VERSION ""

NS_ :

BS_:

BU_: HU ICM BSDR TCO BCM TBOX LDWS BSDL

BO_ 683 BCM_2AB: 8 BCM
 SG_ SecurityStatus : 0|1@0+ (1,0) [0|1] ""  BSDL,BSDR
 SG_ SecurityAlarm : 1|1@0+ (1,0) [0|1] "" Vector__XXX
 SG_ DrvLockCommand : 5|4@0+ (1,0) [0|15] "" Vector__XXX
 SG_ KSEnable : 7|1@0+ (1,0) [0|1] "" Vector__XXX
 SG_ DRLLamp : 9|1@0+ (1,0) [0|1] ""  ICM
 SG_ DayNightStatus : 10|1@0+ (1,0) [0|1] "" Vector__XXX
 SG_ BCM_RemoteKeyID : 13|3@0+ (1,0) [0|7] "" Vector__XXX
 SG_ BackLightControl : 15|2@0+ (1,0) [0|3] "" Vector__XXX
 SG_ LockCtrl : 23|8@0+ (1,0) [0|255] "" Vector__XXX
 SG_ BCM_BackLightLvl : 31|8@0+ (0.4,0) [14.4|86.4] "%"  ICM
 SG_ DirIndicationLeft : 32|1@0+ (1,0) [0|1] ""  ICM,BSDL,BSDR
 SG_ DirIndicationRight : 33|1@0+ (1,0) [0|1] ""  ICM,BSDL,BSDR
 SG_ TurnSwitch : 35|2@0+ (1,0) [0|3] ""  BSDL,BSDR
 SG_ HandBrakingStatus : 36|1@0+ (1,0) [0|1] ""  ICM
 SG_ KeyState : 42|3@0+ (1,0) [0|7] ""  ICM,HU,BSDL,BSDR
 SG_ BCM_KeyState_VD : 44|2@0+ (1,0) [0|3] ""  ICM
 SG_ TurnSwitchVd : 45|1@0+ (1,0) [0|1] "" Vector__XXX
 SG_ WiperStatus : 47|2@0+ (1,0) [0|3] "" Vector__XXX
 SG_ KeyOnCounter : 55|16@0+ (1,0) [0|65534] "" Vector__XXX

BO_ 717 BCM_2CD: 8 BCM
 SG_ HazardWarningLightStatus : 0|1@0+ (1,0) [0|1] "" Vector__XXX
 SG_ RearWiperCtrl : 2|2@0+ (1,0) [0|3] "" Vector__XXX
 SG_ FrontWindscreenWashSW : 3|1@0+ (1,0) [0|1] "" Vector__XXX
 SG_ FrontWiperIntAutoSW : 4|1@0+ (1,0) [0|1] "" Vector__XXX
 SG_ KeyInHoleStatus : 5|1@0+ (1,0) [0|1] "" Vector__XXX
 SG_ AutoLightSW : 6|1@0+ (1,0) [0|1] ""  ICM
 SG_ BCM_RemoteFeedback : 15|3@0+ (1,0) [0|7] "" Vector__XXX
 SG_ BCM_RemoteAuthstate : 12|2@0+ (1,0) [0|3] "" Vector__XXX
 SG_ FLWindowStatus : 20|1@0+ (1,0) [0|1] "" Vector__XXX
 SG_ FRWindowStatus : 21|1@0+ (1,0) [0|1] "" Vector__XXX
 SG_ RLWindowStatus : 22|1@0+ (1,0) [0|1] "" Vector__XXX
 SG_ RRWindowStatus : 23|1@0+ (1,0) [0|1] "" Vector__XXX
 SG_ KickSNRReq : 34|1@0+ (1,0) [0|1] "" Vector__XXX
 SG_ SRF_PosStatus : 43|4@0+ (1,0) [0|15] "" Vector__XXX
 SG_ BCM_FrontWiperSW : 47|3@0+ (1,0) [0|7] "" Vector__XXX
 SG_ Poslamp : 48|1@0+ (1,0) [0|1] ""  ICM,HU
 SG_ Trunk_BackDoor_Sts : 49|1@0+ (1,0) [0|1] ""  ICM
 SG_ HoodStatus : 51|1@0+ (1,0) [0|1] ""  ICM
 SG_ HeadLampHighBeamCtrl : 52|1@0+ (1,0) [0|1] ""  ICM
 SG_ FrontFogLamp : 53|1@0+ (1,0) [0|1] ""  ICM
 SG_ DRVUnlockState : 54|1@0+ (1,0) [0|1] ""  HU,BSDL,BSDR
 SG_ HeadLampLowBeamCtrl : 55|1@0+ (1,0) [0|1] ""  ICM
 SG_ DrvDoorStatus : 56|1@0+ (1,0) [0|1] ""  ICM,HU,BSDL,BSDR
 SG_ PsgDoorStatus : 57|1@0+ (1,0) [0|1] ""  ICM,BSDL,BSDR
 SG_ RRDoorStatus : 58|1@0+ (1,0) [0|1] ""  ICM,BSDL,BSDR
 SG_ RLDoorStatus : 59|1@0+ (1,0) [0|1] ""  ICM
 SG_ DefrostCtrl : 60|1@0+ (1,0) [0|1] "" Vector__XXX
 SG_ RearFogLamp : 61|1@0+ (1,0) [0|1] ""  ICM
 SG_ LeftSeatHeatCtrl : 62|1@0+ (1,0) [0|1] "" Vector__XXX
 SG_ RightSeatHeatCtrl : 63|1@0+ (1,0) [0|1] "" Vector__XXX

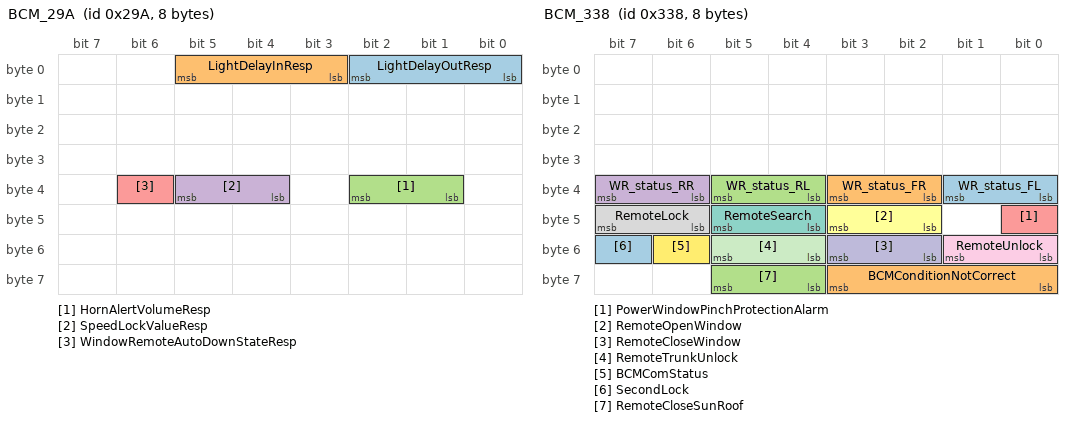
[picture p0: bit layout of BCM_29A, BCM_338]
BO_ 666 BCM_29A: 8 BCM
 SG_ LightDelayOutResp : 2|3@0+ (1,0) [0|7] ""  HU
 SG_ LightDelayInResp : 5|3@0+ (1,0) [0|7] ""  HU
 SG_ HornAlertVolumeResp : 34|2@0+ (1,0) [0|3] ""  HU
 SG_ SpeedLockValueResp : 37|2@0+ (1,0) [0|3] ""  HU
 SG_ WindowRemoteAutoDownStateResp : 38|1@0+ (1,0) [0|1] ""  HU

BO_ 824 BCM_338: 8 BCM
 SG_ WR_status_FL : 33|2@0+ (1,0) [0|3] "" Vector__XXX
 SG_ WR_status_FR : 35|2@0+ (1,0) [0|3] "" Vector__XXX
 SG_ WR_status_RL : 37|2@0+ (1,0) [0|3] "" Vector__XXX
 SG_ WR_status_RR : 39|2@0+ (1,0) [0|3] "" Vector__XXX
 SG_ PowerWindowPinchProtectionAlarm : 40|1@0+ (1,0) [0|1] "" Vector__XXX
 SG_ RemoteOpenWindow : 43|2@0+ (1,0) [0|3] "" Vector__XXX
 SG_ RemoteSearch : 45|2@0+ (1,0) [0|3] ""  TBOX
 SG_ RemoteLock : 47|2@0+ (1,0) [0|3] ""  TBOX
 SG_ RemoteUnlock : 49|2@0+ (1,0) [0|3] ""  TBOX
 SG_ RemoteCloseWindow : 51|2@0+ (1,0) [0|3] ""  TBOX
 SG_ RemoteTrunkUnlock : 53|2@0+ (1,0) [0|3] ""  TBOX
 SG_ BCMComStatus : 54|1@0+ (1,0) [0|1] ""  TBOX
 SG_ SecondLock : 55|1@0+ (1,0) [0|1] ""  TBOX
 SG_ BCMConditionNotCorrect : 59|4@0+ (1,0) [0|15] ""  TBOX
 SG_ RemoteCloseSunRoof : 61|2@0+ (1,0) [0|3] "" Vector__XXX

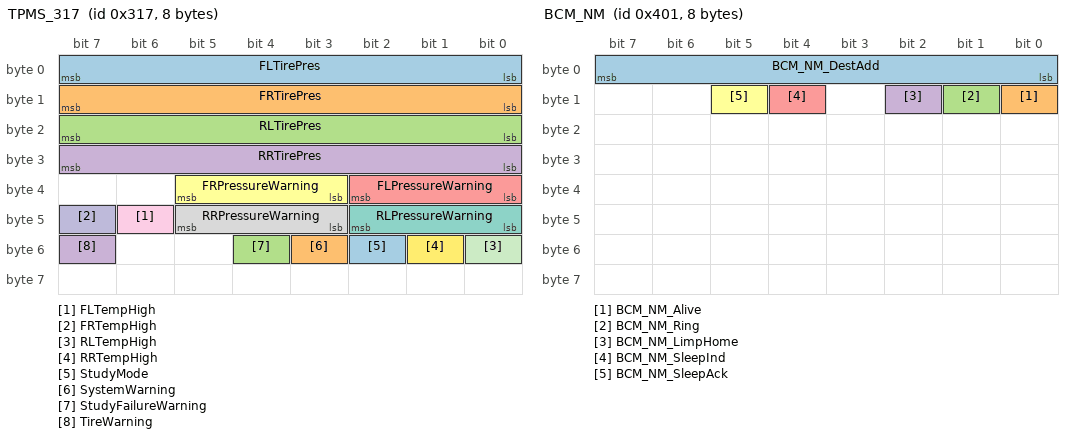
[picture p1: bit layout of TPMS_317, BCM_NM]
BO_ 791 TPMS_317: 8 BCM
 SG_ FLTirePres : 7|8@0+ (2.75,0) [0|698.5] "kpa"  ICM,HU
 SG_ FRTirePres : 15|8@0+ (2.75,0) [0|698.5] "kpa"  ICM,HU
 SG_ RLTirePres : 23|8@0+ (2.75,0) [0|698.5] "kpa"  ICM,HU
 SG_ RRTirePres : 31|8@0+ (2.75,0) [0|698.5] "kpa"  ICM,HU
 SG_ FLPressureWarning : 34|3@0+ (1,0) [0|7] ""  ICM,HU
 SG_ FRPressureWarning : 37|3@0+ (1,0) [0|7] ""  ICM,HU
 SG_ RLPressureWarning : 42|3@0+ (1,0) [0|7] ""  ICM,HU
 SG_ RRPressureWarning : 45|3@0+ (1,0) [0|7] ""  ICM,HU
 SG_ FLTempHigh : 46|1@0+ (1,0) [0|1] ""  ICM,HU
 SG_ FRTempHigh : 47|1@0+ (1,0) [0|1] ""  ICM,HU
 SG_ RLTempHigh : 48|1@0+ (1,0) [0|1] ""  ICM,HU
 SG_ RRTempHigh : 49|1@0+ (1,0) [0|1] ""  ICM,HU
 SG_ StudyMode : 50|1@0+ (1,0) [0|1] ""  HU
 SG_ SystemWarning : 51|1@0+ (1,0) [0|1] ""  ICM,HU
 SG_ StudyFailureWarning : 52|1@0+ (1,0) [0|1] ""  HU
 SG_ TireWarning : 55|1@0+ (1,0) [0|1] ""  ICM,HU

BO_ 930 TPMS_3A2: 8 BCM
 SG_ FLTireTemp : 7|8@0+ (1,-40) [-40|125] "°C"  ICM,HU
 SG_ FRTireTemp : 15|8@0+ (1,-40) [-40|125] "°C"  ICM,HU
 SG_ RLTireTemp : 23|8@0+ (1,-40) [-40|125] "°C"  ICM,HU
 SG_ RRTireTemp : 31|8@0+ (1,-40) [-40|125] "°C"  ICM,HU

BO_ 1025 BCM_NM: 8 BCM
 SG_ BCM_NM_DestAdd : 7|8@0+ (1,0) [0|255] ""  ICM,HU,TBOX
 SG_ BCM_NM_Alive : 8|1@0+ (1,0) [0|1] ""  ICM,HU,TBOX
 SG_ BCM_NM_Ring : 9|1@0+ (1,0) [0|1] ""  ICM,HU,TBOX
 SG_ BCM_NM_LimpHome : 10|1@0+ (1,0) [0|1] ""  ICM,HU,TBOX
 SG_ BCM_NM_SleepInd : 12|1@0+ (1,0) [0|1] ""  ICM,HU,TBOX
 SG_ BCM_NM_SleepAck : 13|1@0+ (1,0) [0|1] ""  ICM,HU,TBOX

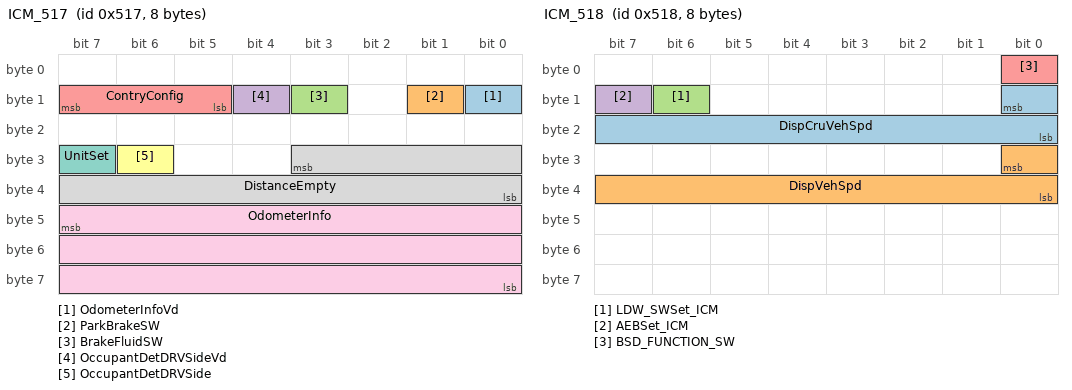
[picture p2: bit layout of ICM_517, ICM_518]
BO_ 1303 ICM_517: 8 ICM
 SG_ OdometerInfoVd : 8|1@0+ (1,0) [0|1] ""  BCM,TBOX,BSDL,BSDR
 SG_ ParkBrakeSW : 9|1@0+ (1,0) [0|1] ""  BCM
 SG_ BrakeFluidSW : 11|1@0+ (1,0) [0|1] "" Vector__XXX
 SG_ OccupantDetDRVSideVd : 12|1@0+ (1,0) [0|1] ""  BCM,HU
 SG_ ContryConfig : 15|3@0+ (1,0) [0|7] "" Vector__XXX
 SG_ OccupantDetDRVSide : 30|1@0+ (1,0) [0|1] ""  HU
 SG_ UnitSet : 31|1@0+ (1,0) [0|1] "" Vector__XXX
 SG_ DistanceEmpty : 27|12@0+ (1,0) [0|2000] "" Vector__XXX
 SG_ OdometerInfo : 47|24@0+ (0.1,0) [0|999999] "km"  BCM,TBOX,BSDL,BSDR

BO_ 1304 ICM_518: 8 ICM
 SG_ DispCruVehSpd : 8|9@0+ (1,0) [0|300] "km/h" Vector__XXX
 SG_ DispVehSpd : 24|9@0+ (1,0) [0|300] "km/h" Vector__XXX
 SG_ LDW_SWSet_ICM : 14|1@0+ (1,0) [0|1] ""  BCM
 SG_ AEBSet_ICM : 15|1@0+ (1,0) [0|1] ""  BCM
 SG_ BSD_FUNCTION_SW : 0|1@0+ (1,0) [0|1] ""  BCM

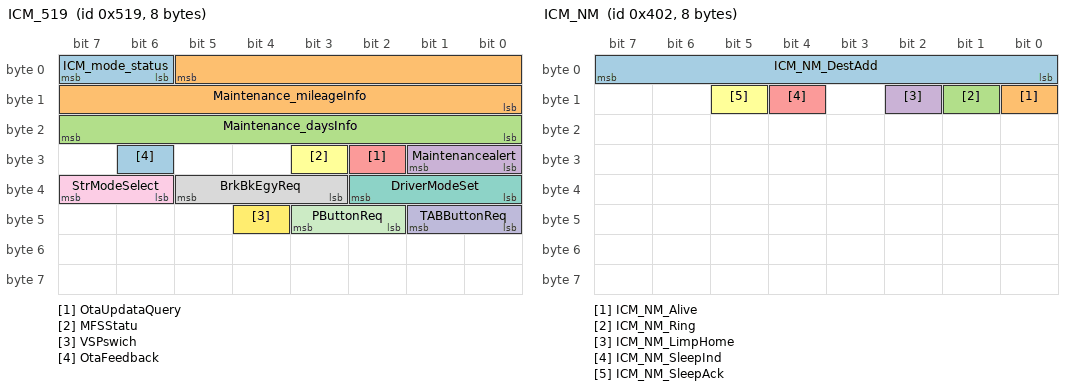
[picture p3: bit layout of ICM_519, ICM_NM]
BO_ 1305 ICM_519: 8 ICM
 SG_ ICM_mode_status : 7|2@0+ (1,0) [0|3] ""  BCM
 SG_ Maintenance_mileageInfo : 5|14@0+ (1,0) [0|10000] ""  BCM,TBOX
 SG_ Maintenance_daysInfo : 23|8@0+ (1,0) [0|180] ""  BCM,TBOX
 SG_ Maintenancealert : 25|2@0+ (1,0) [0|3] ""  BCM,TBOX
 SG_ OtaUpdataQuery : 26|1@0+ (1,0) [0|1] ""  BCM,TBOX
 SG_ MFSStatu : 27|1@0+ (1,0) [0|1] ""  BCM
 SG_ DriverModeSet : 34|3@0+ (1,0) [0|7] ""  BCM
 SG_ BrkBkEgyReq : 37|3@0+ (1,0) [0|7] ""  BCM
 SG_ StrModeSelect : 39|2@0+ (1,0) [0|3] ""  BCM
 SG_ TABButtonReq : 41|2@0+ (1,0) [0|3] ""  BCM
 SG_ PButtonReq : 43|2@0+ (1,0) [0|3] ""  BCM
 SG_ VSPswich : 44|1@0+ (1,0) [0|3] ""  BCM
 SG_ OtaFeedback : 30|1@0+ (1,0) [0|1] ""  BCM,TBOX

BO_ 1026 ICM_NM: 8 ICM
 SG_ ICM_NM_DestAdd : 7|8@0+ (1,0) [0|255] ""  BCM,HU,TBOX
 SG_ ICM_NM_Alive : 8|1@0+ (1,0) [0|1] ""  BCM,HU,TBOX
 SG_ ICM_NM_Ring : 9|1@0+ (1,0) [0|1] ""  BCM,HU,TBOX
 SG_ ICM_NM_LimpHome : 10|1@0+ (1,0) [0|1] ""  BCM,HU,TBOX
 SG_ ICM_NM_SleepInd : 12|1@0+ (1,0) [0|1] ""  BCM,HU,TBOX
 SG_ ICM_NM_SleepAck : 13|1@0+ (1,0) [0|1] ""  BCM,HU,TBOX

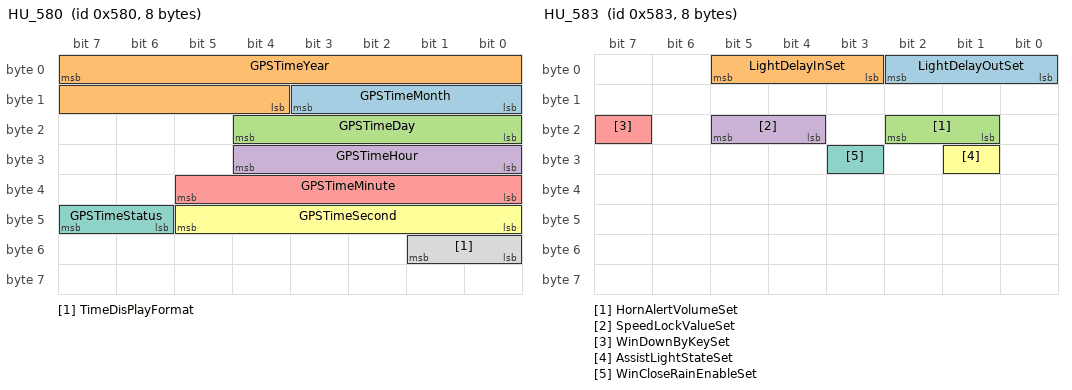
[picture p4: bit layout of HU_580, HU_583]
BO_ 1408 HU_580: 8 HU
 SG_ GPSTimeMonth : 11|4@0+ (1,0) [0|12] "" Vector__XXX
 SG_ GPSTimeYear : 7|12@0+ (1,0) [0|4095] "" Vector__XXX
 SG_ GPSTimeDay : 20|5@0+ (1,0) [0|31] "" Vector__XXX
 SG_ GPSTimeHour : 28|5@0+ (1,0) [0|23] "" Vector__XXX
 SG_ GPSTimeMinute : 37|6@0+ (1,0) [0|59] "" Vector__XXX
 SG_ GPSTimeSecond : 45|6@0+ (1,0) [0|59] "" Vector__XXX
 SG_ GPSTimeStatus : 47|2@0+ (1,0) [0|3] "" Vector__XXX
 SG_ TimeDisPlayFormat : 49|2@0+ (1,0) [0|3] "" Vector__XXX

BO_ 1411 HU_583: 8 HU
 SG_ LightDelayOutSet : 2|3@0+ (1,0) [0|7] ""  BCM
 SG_ LightDelayInSet : 5|3@0+ (1,0) [0|7] ""  BCM
 SG_ HornAlertVolumeSet : 18|2@0+ (1,0) [0|3] ""  BCM
 SG_ SpeedLockValueSet : 21|2@0+ (1,0) [0|3] ""  BCM
 SG_ WinDownByKeySet : 23|1@0+ (1,0) [0|1] ""  BCM
 SG_ AssistLightStateSet : 25|1@0+ (1,0) [0|1] ""  BCM
 SG_ WinCloseRainEnableSet : 27|1@0+ (1,0) [0|1] ""  BCM

BO_ 1525 HU_5F5: 8 HU
 SG_ HU_TBOX_WiFi_Req : 2|1@0+ (1,0) [0|1] ""  TBOX
 SG_ HU_TBOX_SN_Req : 3|1@0+ (1,0) [0|1] ""  TBOX
 SG_ HU_TBOX_VIN_Req : 4|1@0+ (1,0) [0|1] ""  TBOX

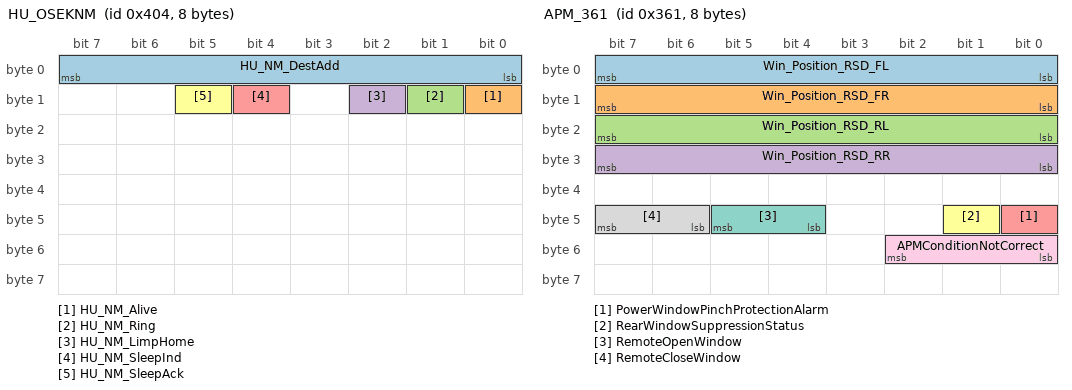
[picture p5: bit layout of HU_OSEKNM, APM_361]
BO_ 1028 HU_OSEKNM: 8 HU
 SG_ HU_NM_DestAdd : 7|8@0+ (1,0) [0|255] ""  BCM,ICM,TBOX
 SG_ HU_NM_Alive : 8|1@0+ (1,0) [0|1] ""  BCM,ICM,TBOX
 SG_ HU_NM_Ring : 9|1@0+ (1,0) [0|1] ""  BCM,ICM,TBOX
 SG_ HU_NM_LimpHome : 10|1@0+ (1,0) [0|1] ""  BCM,ICM,TBOX
 SG_ HU_NM_SleepInd : 12|1@0+ (1,0) [0|1] ""  BCM,ICM,TBOX
 SG_ HU_NM_SleepAck : 13|1@0+ (1,0) [0|1] ""  BCM,ICM,TBOX

BO_ 865 APM_361: 8 BCM
 SG_ Win_Position_RSD_FL : 7|8@0+ (0.5,0) [0|100] "%"  TBOX
 SG_ Win_Position_RSD_FR : 15|8@0+ (0.5,0) [0|100] "%"  TBOX
 SG_ Win_Position_RSD_RL : 23|8@0+ (0.5,0) [0|100] "%"  TBOX
 SG_ Win_Position_RSD_RR : 31|8@0+ (0.5,0) [0|100] "%"  TBOX
 SG_ PowerWindowPinchProtectionAlarm : 40|1@0+ (1,0) [0|1] "" Vector__XXX
 SG_ RearWindowSuppressionStatus : 41|1@0+ (1,0) [0|1] "" Vector__XXX
 SG_ RemoteOpenWindow : 45|2@0+ (1,0) [0|3] "" Vector__XXX
 SG_ RemoteCloseWindow : 47|2@0+ (1,0) [0|3] "" Vector__XXX
 SG_ APMConditionNotCorrect : 50|3@0+ (1,0) [0|7] "" Vector__XXX

BO_ 691 LDFC_2B3: 8 LDWS
 SG_ LDW_Warning : 1|2@0+ (1,0) [0|3] ""  ICM
 SG_ FCW_Warning : 3|2@0+ (1,0) [0|3] ""  ICM
 SG_ camera_status : 4|1@0+ (1,0) [0|1] ""  ICM
 SG_ LDW_Status : 9|2@0+ (1,0) [0|3] ""  ICM
 SG_ FCW_Status : 11|2@0+ (1,0) [0|3] ""  ICM
 SG_ LDW_Button : 15|1@0+ (1,0) [0|1] ""  ICM
 SG_ FCW_Button : 16|1@0+ (1,0) [0|1] ""  ICM
 SG_ LDWSResp : 17|1@0+ (1,0) [0|1] "" Vector__XXX
 SG_ FCWResp : 18|1@0+ (1,0) [0|1] "" Vector__XXX
 SG_ LDFC_NotWarning1 : 23|1@0+ (1,0) [0|1] "" Vector__XXX
 SG_ LDFC_NotWarning2 : 24|1@0+ (1,0) [0|1] "" Vector__XXX
 SG_ LDFC_NotWarning3 : 25|1@0+ (1,0) [0|1] "" Vector__XXX
 SG_ LDFC_NotWarning4 : 26|1@0+ (1,0) [0|1] "" Vector__XXX
 SG_ LDFC_NotWarning5 : 27|1@0+ (1,0) [0|1] "" Vector__XXX
 SG_ LDFC_NotWarning6 : 28|1@0+ (1,0) [0|1] "" Vector__XXX
 SG_ LeftLaneTrack : 33|2@0+ (1,0) [0|3] "" Vector__XXX
 SG_ RightLaneTrack : 35|2@0+ (1,0) [0|3] "" Vector__XXX
 SG_ RightLaneDistance : 47|8@0+ (1,0) [0|250] "cm" Vector__XXX
 SG_ LeftLaneDistance : 55|8@0+ (1,0) [0|250] "cm" Vector__XXX
 SG_ FrontObstacleDistance : 63|8@0+ (1,0) [0|250] "m" Vector__XXX

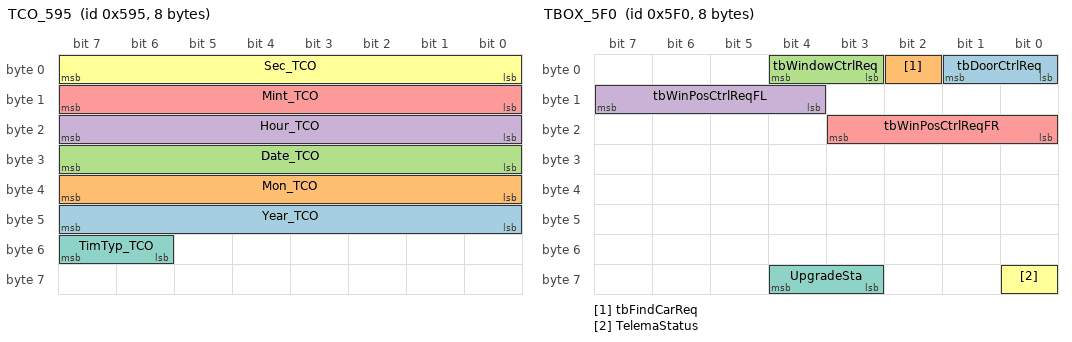
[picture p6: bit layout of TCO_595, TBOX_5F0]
BO_ 1429 TCO_595: 8 TCO
 SG_ Year_TCO : 47|8@0+ (1,2000) [2000|2255] ""  BCM
 SG_ Mon_TCO : 39|8@0+ (1,0) [0|12] ""  BCM
 SG_ Date_TCO : 31|8@0+ (1,0) [0|31] ""  BCM
 SG_ Hour_TCO : 23|8@0+ (1,0) [0|24] ""  BCM
 SG_ Mint_TCO : 15|8@0+ (1,0) [0|59] ""  BCM
 SG_ Sec_TCO : 7|8@0+ (1,0) [0|59] ""  BCM
 SG_ TimTyp_TCO : 55|2@0+ (1,0) [0|3] ""  BCM

BO_ 1520 TBOX_5F0: 8 TBOX
 SG_ tbDoorCtrlReq : 1|2@0+ (1,0) [0|2] ""  BCM
 SG_ tbFindCarReq : 2|1@0+ (1,0) [0|1] ""  BCM
 SG_ tbWindowCtrlReq : 4|2@0+ (1,0) [0|2] ""  BCM
 SG_ tbWinPosCtrlReqFL : 15|4@0+ (1,0) [0|15] ""  BCM
 SG_ tbWinPosCtrlReqFR : 19|4@0+ (1,0) [0|15] ""  BCM
 SG_ TelemaStatus : 56|1@0+ (1,0) [0|1] ""  BCM
 SG_ UpgradeSta : 60|2@0+ (1,0) [0|3] ""  BCM

BO_ 1521 TBOX_5F1: 8 TBOX
 SG_ OtaUpdateTime : 7|8@0+ (1,0) [0|255] "min"  ICM
 SG_ OtaUpdateProgress : 11|4@0+ (1,0) [0|5] ""  ICM
 SG_ OtaUpdateNotify : 12|1@0+ (1,0) [0|1] ""  ICM
 SG_ OtaUpdateState : 13|1@0+ (1,0) [0|1] ""  ICM
 SG_ OtaUpdateResult : 16|1@0+ (1,0) [0|1] ""  ICM

BO_ 1524 TBOX_5F4: 8 TBOX
 SG_ WiFiInfo : 0|1@0+ (1,0) [0|1] ""  HU

BO_ 1529 TBOX_5F9: 8 TBOX
 SG_ TBOX_SN : 0|1@0+ (1,0) [0|1] ""  HU

BO_ 1530 TBOX_5FA: 8 TBOX
 SG_ TBOX_VIN : 0|1@0+ (1,0) [0|1] ""  HU

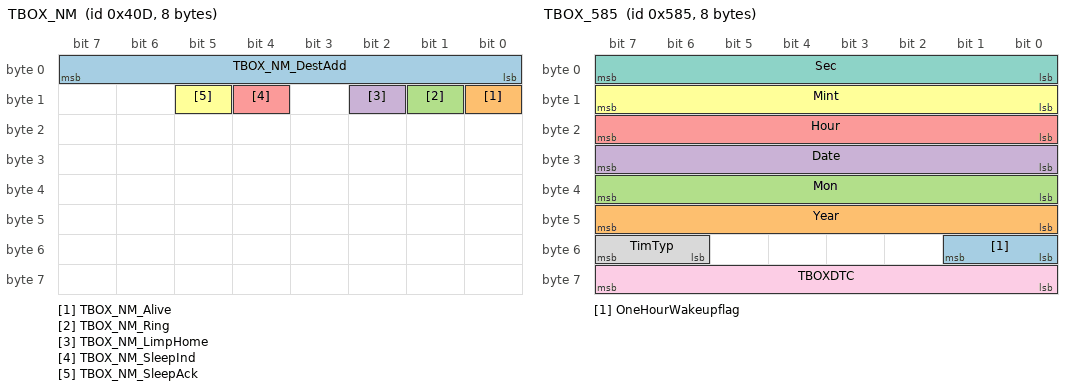
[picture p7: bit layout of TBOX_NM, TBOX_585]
BO_ 1037 TBOX_NM: 8 TBOX
 SG_ TBOX_NM_DestAdd : 7|8@0+ (1,0) [0|255] ""  BCM,ICM,HU
 SG_ TBOX_NM_Alive : 8|1@0+ (1,0) [0|1] ""  BCM,ICM,HU
 SG_ TBOX_NM_Ring : 9|1@0+ (1,0) [0|1] ""  BCM,ICM,HU
 SG_ TBOX_NM_LimpHome : 10|1@0+ (1,0) [0|1] ""  BCM,ICM,HU
 SG_ TBOX_NM_SleepInd : 12|1@0+ (1,0) [0|1] ""  BCM,ICM,HU
 SG_ TBOX_NM_SleepAck : 13|1@0+ (1,0) [0|1] ""  BCM,ICM,HU

BO_ 1413 TBOX_585: 8 TBOX
 SG_ OneHourWakeupflag : 49|2@0+ (1,0) [0|3] ""  BCM,ICM,BSDL,BSDR
 SG_ Year : 47|8@0+ (1,2000) [2000|2255] ""  BCM,ICM,BSDL,BSDR
 SG_ Mon : 39|8@0+ (1,0) [0|12] ""  BCM,ICM,BSDL,BSDR
 SG_ Date : 31|8@0+ (1,0) [0|31] ""  BCM,ICM,BSDL,BSDR
 SG_ Hour : 23|8@0+ (1,0) [0|24] ""  BCM,ICM,BSDL,BSDR
 SG_ Mint : 15|8@0+ (1,0) [0|59] ""  BCM,ICM,BSDL,BSDR
 SG_ Sec : 7|8@0+ (1,0) [0|59] ""  BCM,ICM,BSDL,BSDR
 SG_ TimTyp : 55|2@0+ (1,0) [0|3] ""  BCM,ICM,BSDL,BSDR
 SG_ TBOXDTC : 63|8@0+ (1,0) [0|255] ""  BCM,BSDL,BSDR

BO_ 1672 TBOX_688: 8 TBOX
 SG_ LocationVd : 5|1@0+ (1,0) [0|1] "" Vector__XXX
 SG_ LatitudeDir : 6|1@0+ (1,0) [0|1] "" Vector__XXX
 SG_ LongitudeDir : 7|1@0+ (1,0) [0|1] "" Vector__XXX
 SG_ GPSSpd : 39|16@0+ (0.1,0) [0|220] "km/h" Vector__XXX
 SG_ GPSDirection : 55|16@0+ (1,0) [0|359] "/" Vector__XXX

BO_ 1673 TBOX_589: 8 TBOX
 SG_ GPSLongitude : 7|32@0+ (1E-006,0) [0|359] "°" Vector__XXX
 SG_ GPSLatitude : 39|32@0+ (1E-006,0) [0|359] "°" Vector__XXX

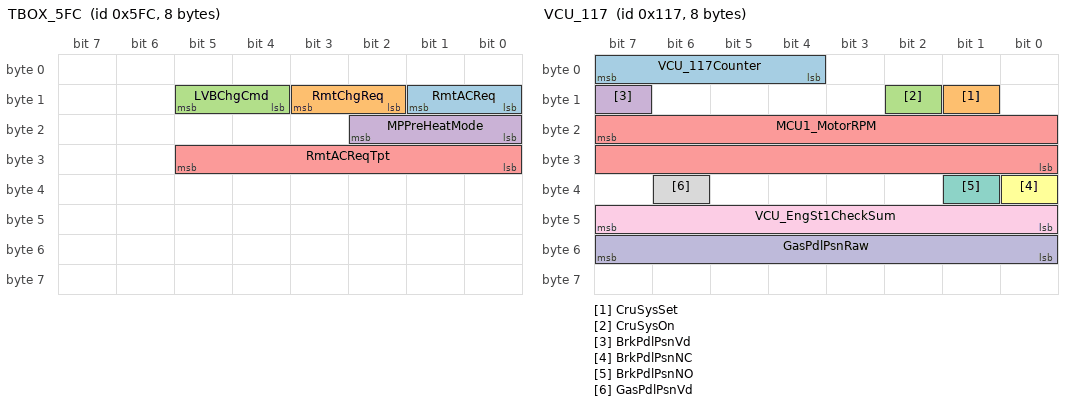
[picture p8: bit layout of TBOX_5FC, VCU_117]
BO_ 1532 TBOX_5FC: 8 TBOX
 SG_ RmtACReq : 9|2@0+ (1,0) [0|3] ""  BCM
 SG_ RmtChgReq : 11|2@0+ (1,0) [0|3] ""  BCM
 SG_ LVBChgCmd : 13|2@0+ (1,0) [0|3] ""  BCM
 SG_ MPPreHeatMode : 18|3@0+ (1,0) [0|7] ""  BCM
 SG_ RmtACReqTpt : 29|6@0+ (0.5,0) [0|30] "℃"  BCM

BO_ 279 VCU_117: 8 BCM
 SG_ VCU_117Counter : 7|4@0+ (1,0) [0|15] "" Vector__XXX
 SG_ CruSysSet : 9|1@0+ (1,0) [0|1] ""  ICM
 SG_ CruSysOn : 10|1@0+ (1,0) [0|1] ""  ICM
 SG_ BrkPdlPsnVd : 15|1@0+ (1,0) [0|1] "" Vector__XXX
 SG_ MCU1_MotorRPM : 23|16@0+ (1,-20000) [-20000|45531] "rpm"  ICM
 SG_ BrkPdlPsnNC : 32|1@0+ (1,0) [0|1] "" Vector__XXX
 SG_ BrkPdlPsnNO : 33|1@0+ (1,0) [0|1] "" Vector__XXX
 SG_ GasPdlPsnVd : 38|1@0+ (1,0) [0|1] "" Vector__XXX
 SG_ VCU_EngSt1CheckSum : 47|8@0+ (1,0) [0|255] "" Vector__XXX
 SG_ GasPdlPsnRaw : 55|8@0+ (0.3937,0) [0|99.9998] "%" Vector__XXX

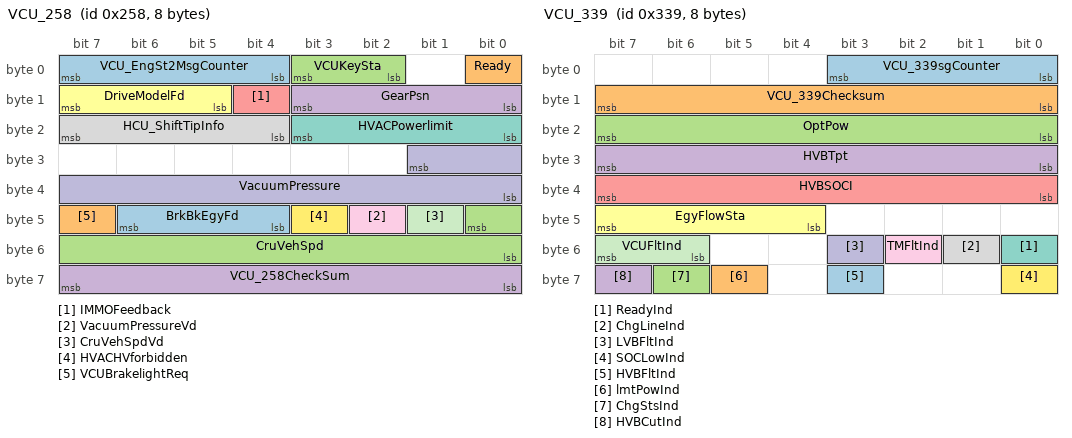
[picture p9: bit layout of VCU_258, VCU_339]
BO_ 600 VCU_258: 8 BCM
 SG_ VCU_EngSt2MsgCounter : 7|4@0+ (1,0) [0|15] "" Vector__XXX
 SG_ Ready : 0|1@0+ (1,0) [0|1] "" Vector__XXX
 SG_ VCUKeySta : 3|2@0+ (1,0) [0|3] "" Vector__XXX
 SG_ GearPsn : 11|4@0+ (1,0) [0|15] ""  ICM,TBOX,BSDL,BSDR
 SG_ IMMOFeedback : 12|1@0+ (1,0) [0|1] ""  ICM
 SG_ DriveModelFd : 15|3@0+ (1,0) [0|7] ""  ICM
 SG_ HVACPowerlimit : 19|4@0+ (0.5,0) [0|7.5] "kW" Vector__XXX
 SG_ HCU_ShiftTipInfo : 23|4@0+ (1,0) [0|15] ""  ICM
 SG_ VacuumPressureVd : 42|1@0+ (1,0) [0|1] "" Vector__XXX
 SG_ VacuumPressure : 25|10@0+ (0.2,-108) [-108|5] "Kpa" Vector__XXX
 SG_ CruVehSpdVd : 41|1@0+ (1,0) [0|1] ""  ICM
 SG_ HVACHVforbidden : 43|1@0+ (1,0) [0|1] "" Vector__XXX
 SG_ BrkBkEgyFd : 46|3@0+ (1,0) [0|7] ""  ICM
 SG_ VCUBrakelightReq : 47|1@0+ (1,0) [0|1] "" Vector__XXX
 SG_ CruVehSpd : 40|9@0+ (1,0) [0|300] "km/h"  ICM
 SG_ VCU_258CheckSum : 63|8@0+ (1,0) [0|255] "" Vector__XXX

BO_ 825 VCU_339: 8 BCM
 SG_ VCU_339sgCounter : 3|4@0+ (1,0) [0|15] "" Vector__XXX
 SG_ VCU_339Checksum : 15|8@0+ (1,0) [0|255] "" Vector__XXX
 SG_ OptPow : 23|8@0+ (1,-40) [-40|214] "kW"  ICM
 SG_ HVBTpt : 31|8@0+ (1,-50) [-50|200] "℃"  ICM
 SG_ HVBSOCI : 39|8@0+ (0.5,0) [0|100] "%"  ICM
 SG_ EgyFlowSta : 47|4@0+ (1,0) [0|15] ""  ICM
 SG_ ReadyInd : 48|1@0+ (1,0) [0|1] ""  ICM
 SG_ ChgLineInd : 49|1@0+ (1,0) [0|1] ""  ICM
 SG_ TMFltInd : 50|1@0+ (1,0) [0|1] ""  ICM
 SG_ LVBFltInd : 51|1@0+ (1,0) [0|1] ""  ICM
 SG_ VCUFltInd : 55|2@0+ (1,0) [0|3] ""  ICM
 SG_ SOCLowInd : 56|1@0+ (1,0) [0|1] ""  ICM
 SG_ HVBFltInd : 59|1@0+ (1,0) [0|1] ""  ICM
 SG_ lmtPowInd : 61|1@0+ (1,0) [0|1] ""  ICM
 SG_ ChgStsInd : 62|1@0+ (1,0) [0|1] ""  ICM
 SG_ HVBCutInd : 63|1@0+ (1,0) [0|1] ""  ICM

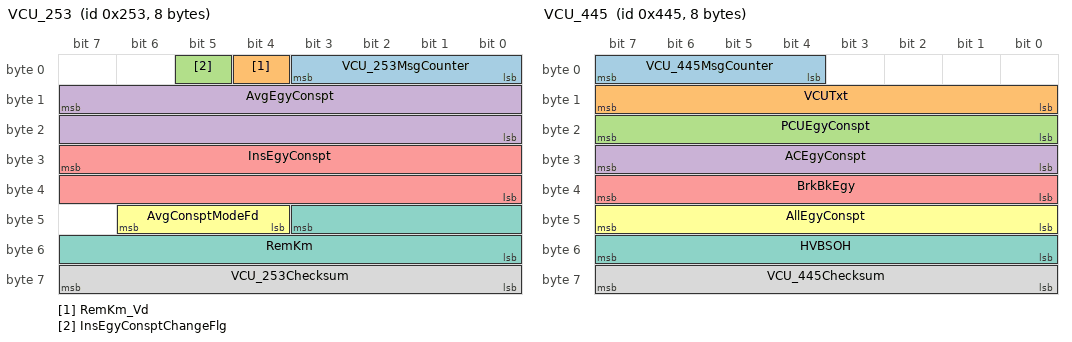
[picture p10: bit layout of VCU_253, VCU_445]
BO_ 595 VCU_253: 8 BCM
 SG_ VCU_253MsgCounter : 3|4@0+ (1,0) [0|15] ""  ICM
 SG_ RemKm_Vd : 4|1@0+ (1,0) [0|1] ""  ICM
 SG_ InsEgyConsptChangeFlg : 5|1@0+ (1,0) [0|1] "" Vector__XXX
 SG_ AvgEgyConspt : 15|16@0+ (0.1,-3276.8) [-3276.8|3276.7] "kWh/100km"  ICM
 SG_ InsEgyConspt : 31|16@0+ (0.1,-3276.8) [-3276.8|3276.7] "kWh/100km"  ICM
 SG_ AvgConsptModeFd : 46|3@0+ (1,0) [0|7] "" Vector__XXX
 SG_ RemKm : 43|12@0+ (1,0) [0|4095] "km"  ICM
 SG_ VCU_253Checksum : 63|8@0+ (1,0) [0|255] ""  ICM

BO_ 1093 VCU_445: 8 BCM
 SG_ VCU_445MsgCounter : 7|4@0+ (1,0) [0|15] "" Vector__XXX
 SG_ VCUTxt : 15|8@0+ (1,0) [0|255] ""  ICM
 SG_ PCUEgyConspt : 23|8@0+ (1,0) [0|255] "KW" Vector__XXX
 SG_ ACEgyConspt : 31|8@0+ (0.1,0) [0|25.5] "KW" Vector__XXX
 SG_ BrkBkEgy : 39|8@0+ (1,0) [0|255] "KW" Vector__XXX
 SG_ AllEgyConspt : 47|8@0+ (1,0) [0|255] "KW" Vector__XXX
 SG_ HVBSOH : 55|8@0+ (1,0) [0|100] "%" Vector__XXX
 SG_ VCU_445Checksum : 63|8@0+ (1,0) [0|255] "" Vector__XXX

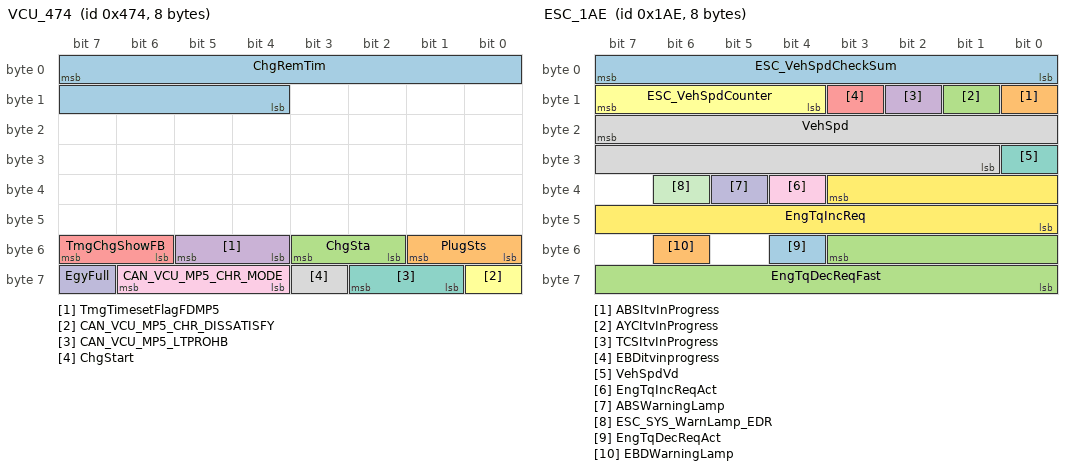
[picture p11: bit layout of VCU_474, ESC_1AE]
BO_ 1140 VCU_474: 8 BCM
 SG_ ChgRemTim : 7|12@0+ (1,0) [0|4095] "min"  ICM
 SG_ PlugSts : 49|2@0+ (1,0) [0|3] "" Vector__XXX
 SG_ ChgSta : 51|2@0+ (1,0) [0|3] "" Vector__XXX
 SG_ TmgTimesetFlagFDMP5 : 53|2@0+ (1,0) [0|3] "" Vector__XXX
 SG_ TmgChgShowFB : 55|2@0+ (1,0) [0|3] "" Vector__XXX
 SG_ CAN_VCU_MP5_CHR_DISSATISFY : 56|1@0+ (1,0) [0|1] "" Vector__XXX
 SG_ CAN_VCU_MP5_LTPROHB : 58|2@0+ (1,0) [0|3] "" Vector__XXX
 SG_ ChgStart : 59|1@0+ (1,0) [0|1] ""  ICM
 SG_ CAN_VCU_MP5_CHR_MODE : 62|3@0+ (1,0) [0|7] "" Vector__XXX
 SG_ EgyFull : 63|1@0+ (1,0) [0|1] ""  ICM

BO_ 612 VCU_264: 8 BCM
 SG_ ACONRemKm : 7|16@0+ (1,0) [0|65535] "km" Vector__XXX
 SG_ ACOFFRemKm : 23|16@0+ (1,0) [0|65535] "km" Vector__XXX
 SG_ VCU_Voltage : 39|16@0+ (0.01,0) [0|655.34] "V"  ICM
 SG_ VCU_Current : 55|16@0+ (0.1,-1000) [-1000|1000] "A"  ICM

BO_ 430 ESC_1AE: 8 BCM
 SG_ ESC_VehSpdCheckSum : 7|8@0+ (1,0) [0|255] "" Vector__XXX
 SG_ ABSItvInProgress : 8|1@0+ (1,0) [0|1] "" Vector__XXX
 SG_ AYCItvInProgress : 9|1@0+ (1,0) [0|1] "" Vector__XXX
 SG_ TCSItvInProgress : 10|1@0+ (1,0) [0|1] "" Vector__XXX
 SG_ EBDitvinprogress : 11|1@0+ (1,0) [0|1] "" Vector__XXX
 SG_ ESC_VehSpdCounter : 15|4@0+ (1,0) [0|15] "" Vector__XXX
 SG_ VehSpdVd : 24|1@0+ (1,0) [0|1] ""  ICM,HU,TBOX,BSDL,BSDR
 SG_ VehSpd : 23|15@0+ (0.05625,0) [0|299.98] "km/h"  ICM,HU,TBOX,BSDL,BSDR
 SG_ EngTqIncReqAct : 36|1@0+ (1,0) [0|1] "" Vector__XXX
 SG_ ABSWarningLamp : 37|1@0+ (1,0) [0|1] ""  TBOX
 SG_ ESC_SYS_WarnLamp_EDR : 38|1@0+ (1,0) [0|1] ""  ICM
 SG_ EngTqIncReq : 35|12@0+ (0.5,-128) [-128|511] "Nm" Vector__XXX
 SG_ EngTqDecReqAct : 52|1@0+ (1,0) [0|1] "" Vector__XXX
 SG_ EBDWarningLamp : 54|1@0+ (1,0) [0|1] ""  TBOX
 SG_ EngTqDecReqFast : 51|12@0+ (0.5,-128) [-128|511] "Nm" Vector__XXX

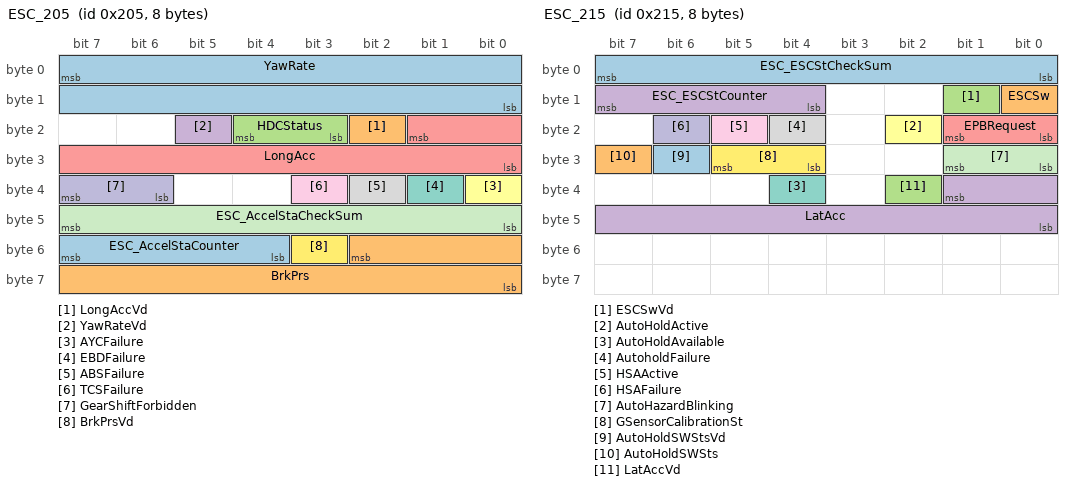
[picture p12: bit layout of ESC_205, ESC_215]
BO_ 517 ESC_205: 8 BCM
 SG_ YawRate : 7|16@0- (0.01,0) [-100|100] "degree/s"  BSDL,BSDR
 SG_ LongAccVd : 18|1@0+ (1,0) [0|1] ""  BSDL,BSDR
 SG_ HDCStatus : 20|2@0+ (1,0) [0|3] ""  ICM
 SG_ YawRateVd : 21|1@0+ (1,0) [0|1] ""  BSDL,BSDR
 SG_ LongAcc : 17|10@0+ (0.01,-1.27) [-1.27|1.27] "g"  BSDL,BSDR
 SG_ AYCFailure : 32|1@0+ (1,0) [0|1] "" Vector__XXX
 SG_ EBDFailure : 33|1@0+ (1,0) [0|1] "" Vector__XXX
 SG_ ABSFailure : 34|1@0+ (1,0) [0|1] "" Vector__XXX
 SG_ TCSFailure : 35|1@0+ (1,0) [0|1] "" Vector__XXX
 SG_ GearShiftForbidden : 39|2@0+ (1,0) [0|3] ""  BSDL,BSDR
 SG_ ESC_AccelStaCheckSum : 47|8@0+ (1,0) [0|255] "" Vector__XXX
 SG_ BrkPrsVd : 51|1@0+ (1,0) [0|1] "" Vector__XXX
 SG_ ESC_AccelStaCounter : 55|4@0+ (1,0) [0|15] "" Vector__XXX
 SG_ BrkPrs : 50|11@0+ (0.1,0) [0|190] "bar" Vector__XXX

BO_ 533 ESC_215: 8 BCM
 SG_ ESC_ESCStCheckSum : 7|8@0+ (1,0) [0|255] "" Vector__XXX
 SG_ ESCSw : 8|1@0+ (1,0) [0|1] "" Vector__XXX
 SG_ ESCSwVd : 9|1@0+ (1,0) [0|1] "" Vector__XXX
 SG_ ESC_ESCStCounter : 15|4@0+ (1,0) [0|15] "" Vector__XXX
 SG_ EPBRequest : 17|2@0+ (1,0) [0|3] "" Vector__XXX
 SG_ AutoHoldActive : 18|1@0+ (1,0) [0|1] ""  ICM
 SG_ AutoHoldAvailable : 36|1@0+ (1,0) [0|1] "" Vector__XXX
 SG_ AutoholdFailure : 20|1@0+ (1,0) [0|1] ""  ICM
 SG_ HSAActive : 21|1@0+ (1,0) [0|1] "" Vector__XXX
 SG_ HSAFailure : 22|1@0+ (1,0) [0|1] "" Vector__XXX
 SG_ AutoHazardBlinking : 25|2@0+ (1,0) [0|3] "" Vector__XXX
 SG_ GSensorCalibrationSt : 29|2@0+ (1,0) [0|3] "" Vector__XXX
 SG_ AutoHoldSWStsVd : 30|1@0+ (1,0) [0|1] "" Vector__XXX
 SG_ AutoHoldSWSts : 31|1@0+ (1,0) [0|1] "" Vector__XXX
 SG_ LatAccVd : 34|1@0+ (1,0) [0|1] ""  BSDL,BSDR
 SG_ LatAcc : 33|10@0+ (0.01,-1.27) [-1.27|1.27] "g"  BSDL,BSDR

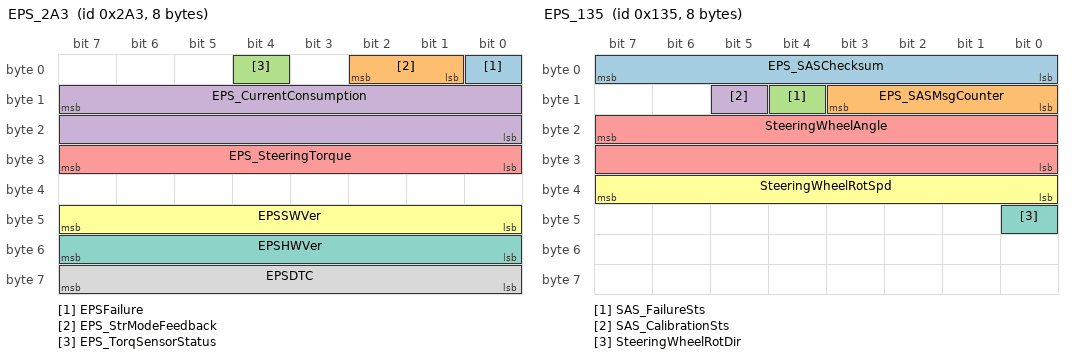
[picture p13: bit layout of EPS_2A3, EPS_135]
BO_ 675 EPS_2A3: 8 BCM
 SG_ EPSFailure : 0|1@0+ (1,0) [0|1] ""  ICM
 SG_ EPS_StrModeFeedback : 2|2@0+ (1,0) [0|3] ""  ICM
 SG_ EPS_TorqSensorStatus : 4|1@0+ (1,0) [0|1] "" Vector__XXX
 SG_ EPS_CurrentConsumption : 15|16@0+ (0.00571,0) [0|120] "A" Vector__XXX
 SG_ EPS_SteeringTorque : 31|8@0+ (0.1794,-22.78) [-8|8] "Nm" Vector__XXX
 SG_ EPSSWVer : 47|8@0+ (1,0) [0|255] ""  TBOX
 SG_ EPSHWVer : 55|8@0+ (1,0) [0|255] ""  TBOX
 SG_ EPSDTC : 63|8@0+ (1,0) [0|255] ""  TBOX

BO_ 309 EPS_135: 8 BCM
 SG_ EPS_SASChecksum : 7|8@0+ (1,0) [0|255] "" Vector__XXX
 SG_ EPS_SASMsgCounter : 11|4@0+ (1,0) [0|15] "" Vector__XXX
 SG_ SAS_FailureSts : 12|1@0+ (1,0) [0|1] ""  BSDL,BSDR
 SG_ SAS_CalibrationSts : 13|1@0+ (1,0) [0|1] ""  ICM,BSDL,BSDR
 SG_ SteeringWheelAngle : 23|16@0+ (0.1,-738) [-738|738] "°"  HU,BSDL,BSDR
 SG_ SteeringWheelRotSpd : 39|8@0+ (4,0) [0|1016] "°/s" Vector__XXX
 SG_ SteeringWheelRotDir : 40|1@0+ (1,0) [0|1] "" Vector__XXX

BO_ 125 ABM_7D: 8 BCM
 SG_ AirbagFailSts : 17|2@0+ (1,0) [0|3] ""  ICM
 SG_ CrashInfo : 8|1@0+ (1,0) [0|1] "" Vector__XXX
 SG_ SRS_StatusCheckSum : 7|8@0+ (1,0) [0|255] "" Vector__XXX
 SG_ SRS_StatusCounter : 15|4@0+ (1,0) [0|15] "" Vector__XXX

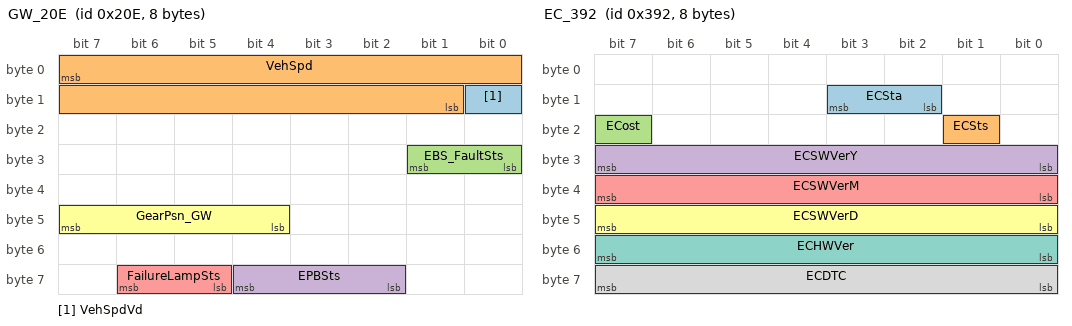
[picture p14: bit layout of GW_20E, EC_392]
BO_ 526 GW_20E: 8 BCM
 SG_ VehSpdVd : 8|1@0+ (1,0) [0|1] ""  HU
 SG_ VehSpd : 7|15@0+ (0.05625,0) [0|299.98] "km/h"  HU
 SG_ EBS_FaultSts : 25|2@0+ (1,0) [0|3] ""  HU
 SG_ EPBSts : 60|3@0+ (1,0) [0|7] ""  ICM,HU,TBOX
 SG_ FailureLampSts : 62|2@0+ (1,0) [0|3] ""  ICM
 SG_ GearPsn_GW : 47|4@0+ (1,0) [0|15] ""  HU

BO_ 945 AC_3B1: 8 BCM
 SG_ ModeDisp : 27|4@0+ (1,0) [0|15] "" Vector__XXX
 SG_ RmtACReqFb : 7|2@0+ (1,0) [0|3] ""  TBOX
 SG_ HVAC_State : 28|1@0+ (1,0) [0|1] ""  TBOX
 SG_ SetTemDisp : 39|8@0+ (0.1,17) [17|32] "°C"  TBOX
 SG_ ExtTempVd : 48|1@0+ (1,0) [0|1] "" Vector__XXX
 SG_ HVAC_RearDefrost : 51|1@0+ (1,0) [0|1] "" Vector__XXX
 SG_ BlowerLvl : 55|4@0+ (1,0) [0|15] ""  TBOX
 SG_ ExtTemp : 63|8@0+ (1,-55) [-55|70] "°C" Vector__XXX

BO_ 947 AC_3B3: 8 BCM
 SG_ IndicatorAutoFront : 1|1@0+ (1,0) [0|1] "" Vector__XXX
 SG_ IndicatorDefrostFront : 2|1@0+ (1,0) [0|1] "" Vector__XXX
 SG_ IndicatorACFront : 3|1@0+ (1,0) [0|1] "" Vector__XXX
 SG_ IndicatorOFFFront : 4|1@0+ (1,0) [0|1] "" Vector__XXX
 SG_ IndicatorIntakeFront : 5|1@0+ (1,0) [0|1] "" Vector__XXX
 SG_ InternalRecycle : 6|1@0+ (1,0) [0|1] "" Vector__XXX
 SG_ HURequest : 59|1@0+ (1,0) [0|1] "" Vector__XXX
 SG_ HUCancel : 60|1@0+ (1,0) [0|1] "" Vector__XXX

BO_ 914 EC_392: 8 BCM
 SG_ ECSta : 11|2@0+ (1,0) [0|3] ""  TBOX
 SG_ ECSts : 17|1@0+ (1,0) [0|1] ""  TBOX
 SG_ ECost : 23|1@0+ (1,0) [0|1] "" Vector__XXX
 SG_ ECSWVerY : 31|8@0+ (1,2015) [2015|2270] "" Vector__XXX
 SG_ ECSWVerM : 39|8@0+ (1,0) [0|12] "" Vector__XXX
 SG_ ECSWVerD : 47|8@0+ (1,0) [0|255] "" Vector__XXX
 SG_ ECHWVer : 55|8@0+ (1,0) [0|255] "" Vector__XXX
 SG_ ECDTC : 63|8@0+ (1,0) [0|255] ""  TBOX

BO_ 1077 AC_435: 8 BCM
 SG_ ACPTCPwrReq : 39|16@0+ (1,0) [0|4500] "W" Vector__XXX
 SG_ PTCTpt : 23|8@0+ (1,-40) [-40|150] "℃"  TBOX
 SG_ PTCRly1Ctl : 27|2@0+ (1,0) [0|3] "" Vector__XXX
 SG_ PTCRly2Ctl : 29|2@0+ (1,0) [0|3] "" Vector__XXX

BO_ 1084 AC_43C: 8 BCM
 SG_ ACDCT : 55|16@0+ (1,0) [0|255] ""  TBOX

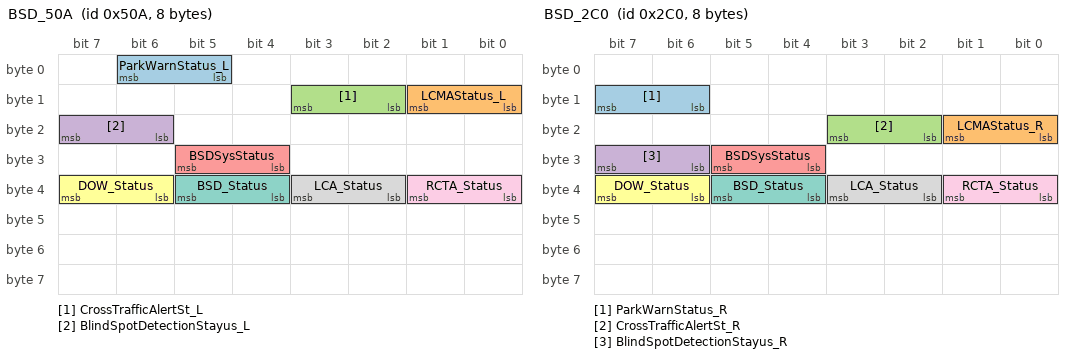
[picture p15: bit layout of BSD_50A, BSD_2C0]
BO_ 1290 BSD_50A: 8 BSDL
 SG_ ParkWarnStatus_L : 6|2@0+ (1,0) [0|2] ""  ICM,HU
 SG_ LCMAStatus_L : 9|2@0+ (1,0) [0|2] ""  ICM,HU
 SG_ CrossTrafficAlertSt_L : 11|2@0+ (1,0) [0|2] ""  ICM,HU
 SG_ BlindSpotDetectionStayus_L : 23|2@0+ (1,0) [0|2] ""  ICM,HU
 SG_ BSDSysStatus : 29|2@0+ (1,0) [0|3] ""  ICM,HU
 SG_ DOW_Status : 39|2@0+ (1,0) [0|3] ""  ICM,HU
 SG_ BSD_Status : 37|2@0+ (1,0) [0|3] ""  ICM,HU
 SG_ LCA_Status : 35|2@0+ (1,0) [0|3] ""  ICM,HU
 SG_ RCTA_Status : 33|2@0+ (1,0) [0|3] ""  ICM,HU

BO_ 704 BSD_2C0: 8 BSDR
 SG_ ParkWarnStatus_R : 15|2@0+ (1,0) [0|2] ""  ICM,HU
 SG_ LCMAStatus_R : 17|2@0+ (1,0) [0|2] ""  ICM,HU
 SG_ CrossTrafficAlertSt_R : 19|2@0+ (1,0) [0|2] ""  ICM,HU
 SG_ BlindSpotDetectionStayus_R : 31|2@0+ (1,0) [0|2] ""  ICM,HU
 SG_ BSDSysStatus : 29|2@0+ (1,0) [0|3] ""  ICM,HU
 SG_ DOW_Status : 39|2@0+ (1,0) [0|3] ""  ICM,HU
 SG_ BSD_Status : 37|2@0+ (1,0) [0|3] ""  ICM,HU
 SG_ LCA_Status : 35|2@0+ (1,0) [0|3] ""  ICM,HU
 SG_ RCTA_Status : 33|2@0+ (1,0) [0|3] ""  ICM,HU

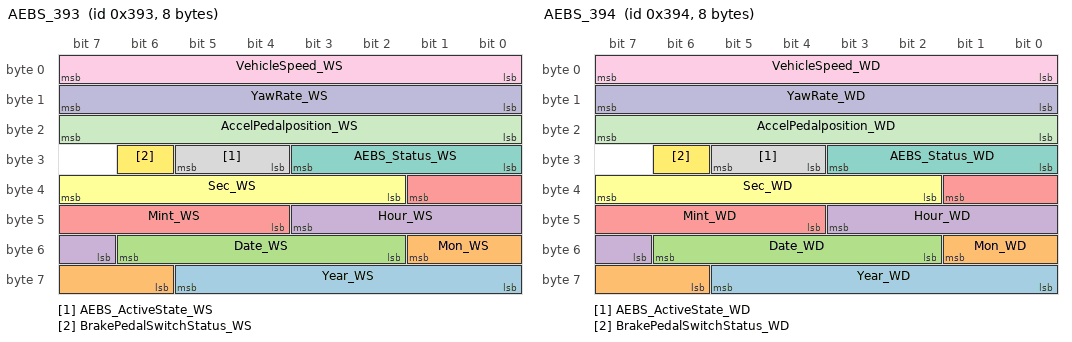
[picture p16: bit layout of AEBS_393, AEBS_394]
BO_ 915 AEBS_393: 8 BCM
 SG_ Year_WS : 61|6@0+ (1,2019) [2019|2082] ""  TBOX
 SG_ Mon_WS : 49|4@0+ (1,0) [0|12] ""  TBOX
 SG_ Date_WS : 54|5@0+ (1,0) [0|31] ""  TBOX
 SG_ Hour_WS : 43|5@0+ (1,0) [0|23] ""  TBOX
 SG_ Mint_WS : 33|6@0+ (1,0) [0|59] ""  TBOX
 SG_ Sec_WS : 39|6@0+ (1,0) [0|59] ""  TBOX
 SG_ AEBS_Status_WS : 27|4@0+ (1,0) [0|15] ""  TBOX
 SG_ AEBS_ActiveState_WS : 29|2@0+ (1,0) [0|1] ""  TBOX
 SG_ VehicleSpeed_WS : 7|8@0+ (1,0) [0|255] "km/h"  TBOX
 SG_ YawRate_WS : 15|8@0+ (0.2,-25.6) [-25.6|25.4] "degree/s"  TBOX
 SG_ AccelPedalposition_WS : 23|8@0+ (0.3937,0) [0|99.9998] "%"  TBOX
 SG_ BrakePedalSwitchStatus_WS : 30|1@0+ (1,0) [0|1] ""  TBOX

BO_ 916 AEBS_394: 8 BCM
 SG_ Year_WD : 61|6@0+ (1,2019) [2019|2082] ""  TBOX
 SG_ Mon_WD : 49|4@0+ (1,0) [0|12] ""  TBOX
 SG_ Date_WD : 54|5@0+ (1,0) [0|31] ""  TBOX
 SG_ Hour_WD : 43|5@0+ (1,0) [0|23] ""  TBOX
 SG_ Mint_WD : 33|6@0+ (1,0) [0|59] ""  TBOX
 SG_ Sec_WD : 39|6@0+ (1,0) [0|59] ""  TBOX
 SG_ AEBS_Status_WD : 27|4@0+ (1,0) [0|15] ""  TBOX
 SG_ AEBS_ActiveState_WD : 29|2@0+ (1,0) [0|1] ""  TBOX
 SG_ VehicleSpeed_WD : 7|8@0+ (1,0) [0|255] "km/h"  TBOX
 SG_ YawRate_WD : 15|8@0+ (0.2,-25.6) [-25.6|25.4] "degree/s"  TBOX
 SG_ AccelPedalposition_WD : 23|8@0+ (0.3937,0) [0|99.9998] "%"  TBOX
 SG_ BrakePedalSwitchStatus_WD : 30|1@0+ (1,0) [0|1] ""  TBOX

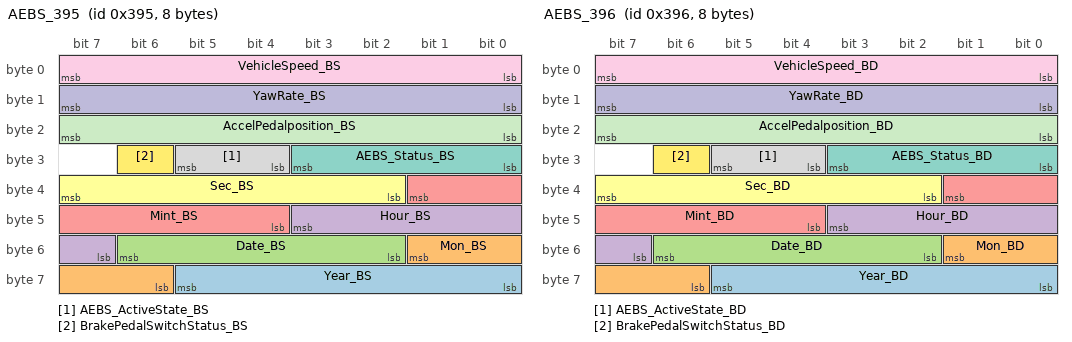
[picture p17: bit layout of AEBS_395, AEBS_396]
BO_ 917 AEBS_395: 8 BCM
 SG_ Year_BS : 61|6@0+ (1,2019) [2019|2082] ""  TBOX
 SG_ Mon_BS : 49|4@0+ (1,0) [0|12] ""  TBOX
 SG_ Date_BS : 54|5@0+ (1,0) [0|31] ""  TBOX
 SG_ Hour_BS : 43|5@0+ (1,0) [0|23] ""  TBOX
 SG_ Mint_BS : 33|6@0+ (1,0) [0|59] ""  TBOX
 SG_ Sec_BS : 39|6@0+ (1,0) [0|59] ""  TBOX
 SG_ AEBS_Status_BS : 27|4@0+ (1,0) [0|15] ""  TBOX
 SG_ AEBS_ActiveState_BS : 29|2@0+ (1,0) [0|1] ""  TBOX
 SG_ VehicleSpeed_BS : 7|8@0+ (1,0) [0|255] "km/h"  TBOX
 SG_ YawRate_BS : 15|8@0+ (0.2,-25.6) [-25.6|25.4] "degree/s"  TBOX
 SG_ AccelPedalposition_BS : 23|8@0+ (0.3937,0) [0|99.9998] "%"  TBOX
 SG_ BrakePedalSwitchStatus_BS : 30|1@0+ (1,0) [0|1] ""  TBOX

BO_ 918 AEBS_396: 8 BCM
 SG_ Year_BD : 61|6@0+ (1,2019) [2019|2082] ""  TBOX
 SG_ Mon_BD : 49|4@0+ (1,0) [0|12] ""  TBOX
 SG_ Date_BD : 54|5@0+ (1,0) [0|31] ""  TBOX
 SG_ Hour_BD : 43|5@0+ (1,0) [0|23] ""  TBOX
 SG_ Mint_BD : 33|6@0+ (1,0) [0|59] ""  TBOX
 SG_ Sec_BD : 39|6@0+ (1,0) [0|59] ""  TBOX
 SG_ AEBS_Status_BD : 27|4@0+ (1,0) [0|15] ""  TBOX
 SG_ AEBS_ActiveState_BD : 29|2@0+ (1,0) [0|1] ""  TBOX
 SG_ VehicleSpeed_BD : 7|8@0+ (1,0) [0|255] "km/h"  TBOX
 SG_ YawRate_BD : 15|8@0+ (0.2,-25.6) [-25.6|25.4] "degree/s"  TBOX
 SG_ AccelPedalposition_BD : 23|8@0+ (0.3937,0) [0|99.9998] "%"  TBOX
 SG_ BrakePedalSwitchStatus_BD : 30|1@0+ (1,0) [0|1] ""  TBOX

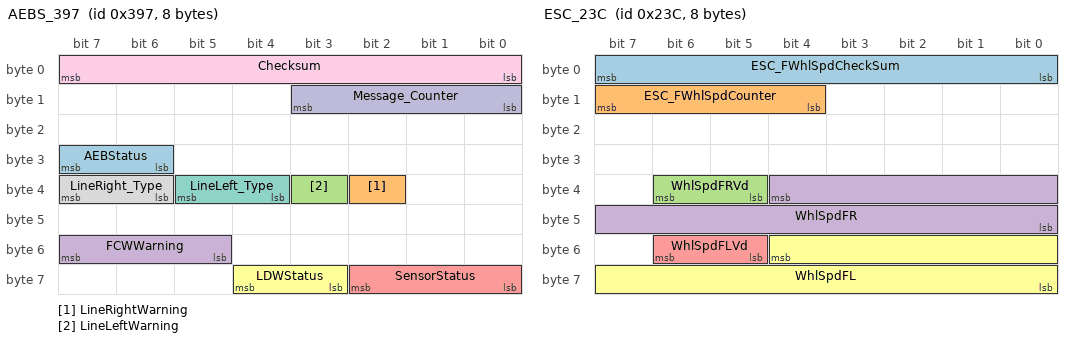
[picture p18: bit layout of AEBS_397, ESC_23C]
BO_ 919 AEBS_397: 8 BCM
 SG_ AEBStatus : 31|2@0+ (1,0) [0|3] ""  ICM,HU
 SG_ LineRightWarning : 34|1@0+ (1,0) [0|1] ""  ICM
 SG_ LineLeftWarning : 35|1@0+ (1,0) [0|1] ""  ICM
 SG_ FCWWarning : 55|3@0+ (1,0) [0|7] ""  ICM
 SG_ SensorStatus : 58|3@0+ (1,0) [0|7] ""  ICM
 SG_ LDWStatus : 60|2@0+ (1,0) [0|3] ""  ICM,HU
 SG_ LineLeft_Type : 37|2@0+ (1,0) [0|7] ""  ICM
 SG_ LineRight_Type : 39|2@0+ (1,0) [0|7] ""  ICM
 SG_ Checksum : 7|8@0+ (1,0) [0|255] "" Vector__XXX
 SG_ Message_Counter : 11|4@0+ (1,0) [0|15] "" Vector__XXX

BO_ 500 GW_1F4: 8 BCM
 SG_ BSD_FUNCTION_SW : 0|1@0+ (1,0) [0|1] ""  BSDL,BSDR
 SG_ Poslamp : 2|1@0+ (1,0) [0|1] "" Vector__XXX
 SG_ Trunk_BackDoor_Sts : 3|1@0+ (1,0) [0|1] "" Vector__XXX
 SG_ PsgDoorStatus : 4|1@0+ (1,0) [0|1] "" Vector__XXX
 SG_ RRDoorStatus : 5|1@0+ (1,0) [0|1] "" Vector__XXX
 SG_ RLDoorStatus : 6|1@0+ (1,0) [0|1] "" Vector__XXX
 SG_ DRVUnlockState : 7|1@0+ (1,0) [0|1] "" Vector__XXX
 SG_ DefrostCtrl : 8|1@0+ (1,0) [0|1] "" Vector__XXX
 SG_ DrvDoorStatus : 10|1@0+ (1,0) [0|1] "" Vector__XXX
 SG_ OccupantDetDRVSideVd : 11|1@0+ (1,0) [0|1] "" Vector__XXX
 SG_ HeadLampLowBeamCtrl : 12|1@0+ (1,0) [0|1] "" Vector__XXX
 SG_ HeadLampHighBeamCtrl : 13|1@0+ (1,0) [0|1] "" Vector__XXX
 SG_ LDW_SWSet : 15|1@0+ (1,0) [0|1] "" Vector__XXX
 SG_ KeyState_GW : 18|3@0+ (1,0) [0|7] ""  BSDL,BSDR
 SG_ HoodStatus : 19|1@0+ (1,0) [0|1] "" Vector__XXX
 SG_ OccupantDetDRVSide : 20|1@0+ (1,0) [0|1] "" Vector__XXX
 SG_ AEBSet : 21|1@0+ (1,0) [0|1] "" Vector__XXX
 SG_ TurnSwitch_GW : 23|2@0+ (1,0) [0|3] "" Vector__XXX
 SG_ FrontWiperStatus_GW : 25|2@0+ (1,0) [0|3] "" Vector__XXX
 SG_ DirIndicationLeft_GW : 32|1@0+ (1,0) [0|1] "" Vector__XXX
 SG_ DirIndicationRight_GW : 33|1@0+ (1,0) [0|1] "" Vector__XXX
 SG_ HazardWarningLightStatus : 34|1@0+ (1,0) [0|1] "" Vector__XXX
 SG_ BCM_KeyState_VD : 38|2@0+ (1,0) [0|3] "" Vector__XXX
 SG_ Checksumof1F4 : 47|8@0+ (1,0) [0|255] "" Vector__XXX
 SG_ TurnSwitchVd : 51|1@0+ (1,0) [0|1] "" Vector__XXX
 SG_ Counterof1F4 : 55|4@0+ (1,0) [0|15] "" Vector__XXX
 SG_ StrModeSelect : 63|2@0+ (1,0) [0|3] "" Vector__XXX

BO_ 572 ESC_23C: 8 BCM
 SG_ ESC_FWhlSpdCheckSum : 7|8@0+ (1,0) [0|255] "" Vector__XXX
 SG_ ESC_FWhlSpdCounter : 15|4@0+ (1,0) [0|15] "" Vector__XXX
 SG_ WhlSpdFRVd : 38|2@0+ (1,0) [0|3] ""  BSDL,BSDR
 SG_ WhlSpdFR : 36|13@0+ (0.05625,0) [0|299.981] "km/h"  BSDL,BSDR
 SG_ WhlSpdFLVd : 54|2@0+ (1,0) [0|3] ""  BSDL,BSDR
 SG_ WhlSpdFL : 52|13@0+ (0.05625,0) [0|299.981] "km/h"  BSDL,BSDR

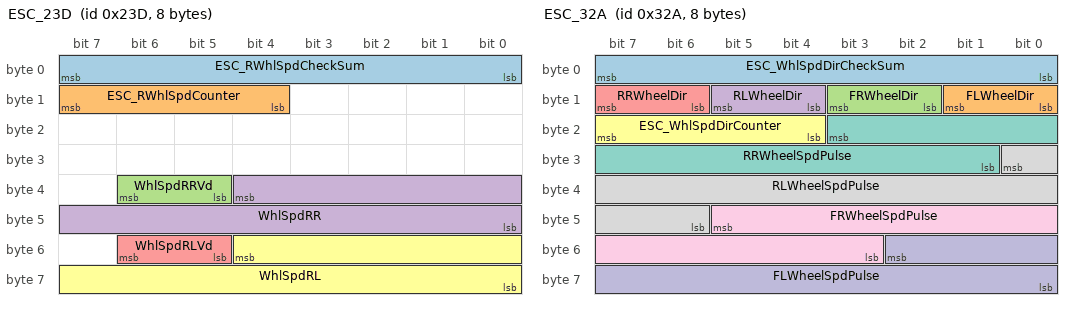
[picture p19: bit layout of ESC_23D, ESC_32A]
BO_ 573 ESC_23D: 8 BCM
 SG_ ESC_RWhlSpdCheckSum : 7|8@0+ (1,0) [0|255] "" Vector__XXX
 SG_ ESC_RWhlSpdCounter : 15|4@0+ (1,0) [0|15] "" Vector__XXX
 SG_ WhlSpdRRVd : 38|2@0+ (1,0) [0|3] ""  BSDL,BSDR
 SG_ WhlSpdRR : 36|13@0+ (0.05625,0) [0|299.981] "km/h"  BSDL,BSDR
 SG_ WhlSpdRLVd : 54|2@0+ (1,0) [0|3] ""  BSDL,BSDR
 SG_ WhlSpdRL : 52|13@0+ (0.05625,0) [0|299.981] "km/h"  BSDL,BSDR

BO_ 810 ESC_32A: 8 BCM
 SG_ ESC_WhlSpdDirCheckSum : 7|8@0+ (1,0) [0|255] "" Vector__XXX
 SG_ FLWheelDir : 9|2@0+ (1,0) [0|3] ""  BSDL,BSDR
 SG_ FRWheelDir : 11|2@0+ (1,0) [0|3] ""  BSDL,BSDR
 SG_ RLWheelDir : 13|2@0+ (1,0) [0|3] ""  BSDL,BSDR
 SG_ RRWheelDir : 15|2@0+ (1,0) [0|3] ""  BSDL,BSDR
 SG_ ESC_WhlSpdDirCounter : 23|4@0+ (1,0) [0|15] "" Vector__XXX
 SG_ RRWheelSpdPulse : 19|11@0+ (1,0) [0|2046] "Pluse"  BSDL,BSDR
 SG_ RLWheelSpdPulse : 24|11@0+ (1,0) [0|2046] "Pluse"  BSDL,BSDR
 SG_ FRWheelSpdPulse : 45|11@0+ (1,0) [0|2046] "Pluse"  BSDL,BSDR
 SG_ FLWheelSpdPulse : 50|11@0+ (1,0) [0|2046] "Pluse"  BSDL,BSDR

BO_ 804 VCU_324: 8 BCM
 SG_ HVBOptPow : 15|8@0+ (1,0) [0|100] "%"  ICM
 SG_ HVAvailablePower : 23|8@0+ (1,0) [0|100] "%"  ICM
 SG_ EgyRecycleOptPow : 31|8@0+ (1,0) [0|100] "%"  ICM
 SG_ EgyRecycleAvailablePower : 39|8@0+ (1,0) [0|100] "%"  ICM

BO_ 809 mrECM_SysStHMI2: 8 BCM
 SG_ RemKMAge_Dyn : 51|12@0+ (1,0) [0|4095] "km"  ICM

CM_ SG_ 683 SecurityStatus "Signal to indicate the car has been defended.";
CM_ SG_ 683 SecurityAlarm "security alarm status";
CM_ SG_ 683 DrvLockCommand "Lock and unlock command from the driver ";
CM_ SG_ 683 KSEnable "this signal is used to Indicates Master starts or stops measuring. KS should be deactivated （使无效）while ignition（点火装置） is on or the vehicle is driving.";
CM_ SG_ 683 DRLLamp "day light indicator
日行灯状态";
CM_ SG_ 683 DayNightStatus "自动灯光判断当前外部灯光状态";
CM_ SG_ 683 BCM_RemoteKeyID "BCM report which remote key ID is on using ";
CM_ SG_ 683 BackLightControl "To control the Engine Switch back light.
背光灯状态";
CM_ SG_ 683 LockCtrl "Used by smart access logic; the software structure
needs this feedback
锁命令";
CM_ SG_ 683 BCM_BackLightLvl "To control the back light brightness.
背光等级";
CM_ SG_ 683 DirIndicationLeft "LH turn light indicator
左转向灯状态，信号值变化和转向灯同频率";
CM_ SG_ 683 DirIndicationRight "RH turn light indicator
右转向灯状态，信号值变化和转向灯同频率";
CM_ SG_ 683 TurnSwitch "转向开关状态";
CM_ SG_ 683 HandBrakingStatus "Hand Braking Status
手刹状态";
CM_ SG_ 683 KeyState "power management feedbackof the Vehicle State.
点火钥匙状态";
CM_ SG_ 683 BCM_KeyState_VD "KeyState signal valid flag
KeyState信号有效标志位";
CM_ SG_ 683 TurnSwitchVd "转向开关状态有效位";
CM_ SG_ 683 WiperStatus " Front wiper Status
前雨刮状态";
CM_ SG_ 683 KeyOnCounter "Every ignition cycle, the counter +1
点火次数级数";
CM_ SG_ 717 HazardWarningLightStatus "Hazard Warning Light  Status
危险警示灯状态";
CM_ SG_ 717 RearWiperCtrl "Rear wiper Status
后雨刮状态";
CM_ SG_ 717 FrontWindscreenWashSW "Front windscreen washing switch status
前挡风玻璃清洗开关状态";
CM_ SG_ 717 FrontWiperIntAutoSW "Front wiper Int or Auto switch
前雨刮间歇或自动雨刮开关状态";
CM_ SG_ 717 KeyInHoleStatus "Key In Hole Status
钥匙插入状态";
CM_ SG_ 717 AutoLightSW "Auto Light SW status
自动灯光开关状态";
CM_ SG_ 717 BCM_RemoteFeedback "Remote Feedback
反馈远程控制状态";
CM_ SG_ 717 BCM_RemoteAuthstate "Remote authentication state
BCM与Tbox认证状态";
CM_ SG_ 717 FLWindowStatus "Front Left side window open/close status
左前窗状态";
CM_ SG_ 717 FRWindowStatus "Front Right side door open/close status
右前窗状态";
CM_ SG_ 717 RLWindowStatus "Rear Left side window open/close status
左后窗状态";
CM_ SG_ 717 RRWindowStatus "Rear Right side door open/close status
右后窗状态";
CM_ SG_ 717 KickSNRReq "KS request 脚踢传感器脚踢请求";
CM_ SG_ 717 SRF_PosStatus "Sunroof position status";
CM_ SG_ 717 BCM_FrontWiperSW " Front wiper switch
前雨刮开关状态";
CM_ SG_ 717 Poslamp "Position Lamp output status
位置灯状态";
CM_ SG_ 717 Trunk_BackDoor_Sts "Trunk door(Tailgate) open/close status
尾门/后备箱门状态";
CM_ SG_ 717 HoodStatus "Hood closing status
引擎盖状态";
CM_ SG_ 717 HeadLampHighBeamCtrl "High beam control
远光灯状态";
CM_ SG_ 717 FrontFogLamp "Front fog lamp output status
前雾灯状态";
CM_ SG_ 717 DRVUnlockState "Driver side door lock/unlock status
左前门锁状态";
CM_ SG_ 717 HeadLampLowBeamCtrl "Low beam control
近光灯状态";
CM_ SG_ 717 DrvDoorStatus "Driver side door open/close status
左前门状态";
CM_ SG_ 717 PsgDoorStatus "Passenger side door open/close status
右前门状态";
CM_ SG_ 717 RRDoorStatus "Rear Right side door open/close status
右后门状态";
CM_ SG_ 717 RLDoorStatus "Rear Left side door open/close status
左后门状态";
CM_ SG_ 717 DefrostCtrl "Rear Defogger Relay Coil Control
后除霜状态";
CM_ SG_ 717 RearFogLamp "Rear Fog lamp
后雾灯状态";
CM_ SG_ 717 LeftSeatHeatCtrl "Left Seat Heat Ctrl";
CM_ SG_ 717 RightSeatHeatCtrl "Right Seat Heat Ctrl";
CM_ SG_ 666 LightDelayOutResp "Light Delay Out Response";
CM_ SG_ 666 LightDelayInResp "Light Delay In Response";
CM_ SG_ 666 HornAlertVolumeResp "Horn alert volume
设防提示音量大小";
CM_ SG_ 666 SpeedLockValueResp "automatic lock when the car speed is over threshold speed value
自动车速锁设置";
CM_ SG_ 666 WindowRemoteAutoDownStateResp "windows automatic down by remote key
遥控自动降窗开启/关闭";
CM_ SG_ 824 WR_status_FL "Window motor state";
CM_ SG_ 824 WR_status_FR "Window motor state";
CM_ SG_ 824 WR_status_RL "Window motor state";
CM_ SG_ 824 WR_status_RR "Window motor state";
CM_ SG_ 824 PowerWindowPinchProtectionAlarm "Window Up Alarm state";
CM_ SG_ 824 RemoteOpenWindow "BCM反馈是否执行开启车窗";
CM_ SG_ 824 RemoteSearch "BCM反馈是否执行寻车";
CM_ SG_ 824 RemoteLock "BCM反馈是否执行上锁";
CM_ SG_ 824 RemoteUnlock "BCM反馈是否执行解锁";
CM_ SG_ 824 RemoteCloseWindow "BCM反馈是否执行关闭车窗";
CM_ SG_ 824 RemoteTrunkUnlock "BCM反馈是否执行开启后备箱";
CM_ SG_ 824 BCMComStatus "BCM节点当前通信状态";
CM_ SG_ 824 SecondLock "BCM执行二次上锁";
CM_ SG_ 824 BCMConditionNotCorrect "BCM反馈未执行远程指令时条件不满足的原因";
CM_ SG_ 824 RemoteCloseSunRoof "BCM反馈是否执行关闭天窗";
CM_ SG_ 791 FLTirePres "Left front tire pressure";
CM_ SG_ 791 FRTirePres "Right front tire pressure";
CM_ SG_ 791 RLTirePres "Left rear tire pressure";
CM_ SG_ 791 RRTirePres "Right rear tire pressure";
CM_ SG_ 791 FLPressureWarning "Left front  tire pressure warning status";
CM_ SG_ 791 FRPressureWarning "Right front  tire pressure warning status";
CM_ SG_ 791 RLPressureWarning "Left rear tire pressure warning status";
CM_ SG_ 791 RRPressureWarning "Right rear tire pressure warning status";
CM_ SG_ 791 FLTempHigh "Left front tire high temperature warning";
CM_ SG_ 791 FRTempHigh "Right front tire high temperature warning";
CM_ SG_ 791 RLTempHigh "Left rear tire high temperature warning";
CM_ SG_ 791 RRTempHigh "Right rear tire high temperature warning";
CM_ SG_ 791 StudyMode "ECU enter studying TPMS mode";
CM_ SG_ 791 SystemWarning "ECU System error";
CM_ SG_ 791 StudyFailureWarning "TPMS Study Failure Warning";
CM_ SG_ 930 FLTireTemp "Left front tire temperature";
CM_ SG_ 930 FRTireTemp "Right front tire temperature";
CM_ SG_ 930 RLTireTemp "Left rear tire temperature";
CM_ SG_ 930 RRTireTemp "Right rear tire temperature";
CM_ SG_ 1025 BCM_NM_DestAdd "OSKE network managament destination address";
CM_ SG_ 1025 BCM_NM_Alive "OSKE network managament alive signal";
CM_ SG_ 1025 BCM_NM_Ring "OSKE network managament Ring signal";
CM_ SG_ 1025 BCM_NM_LimpHome "OSKE network managament limp home signal";
CM_ SG_ 1025 BCM_NM_SleepInd "OSKE network managament bus sleep indication signal";
CM_ SG_ 1025 BCM_NM_SleepAck "OSKE network managament bus sleep acknowledge  signal";
CM_ SG_ 1303 OdometerInfoVd "The valid infomation of the odometer signal.";
CM_ SG_ 1303 ParkBrakeSW "Parking Brake Handle Switch Status";
CM_ SG_ 1303 BrakeFluidSW "Brake fluid warning";
CM_ SG_ 1303 OccupantDetDRVSideVd "主驾安全带开关信号可信度";
CM_ SG_ 1303 ContryConfig "Contry Configuration";
CM_ SG_ 1303 OccupantDetDRVSide "Driver side seatbelt open/close status";
CM_ SG_ 1303 UnitSet "Unit Set
单位设置";
CM_ SG_ 1303 DistanceEmpty "DistanceEmpty
续航里程";
CM_ SG_ 1303 OdometerInfo "Vehicle Odometer information";
CM_ SG_ 1304 DispCruVehSpd "display Cruise Vehicle speed  显示车辆巡航速度";
CM_ SG_ 1304 DispVehSpd "displayed vehicle speed
ICM显示车速";
CM_ SG_ 1304 LDW_SWSet_ICM "LDW systerm set by DVD
LDW系统设置";
CM_ SG_ 1304 AEBSet_ICM "AEBS systerm set by DVD
AEBS系统设置";
CM_ SG_ 1304 BSD_FUNCTION_SW "BSD System On/Off Switch
盲点监测系统开关";
CM_ SG_ 1305 ICM_mode_status "The mode status  of ICM          
仪表模式状态";
CM_ SG_ 1305 Maintenance_mileageInfo "The mileage distance of Maintenance
距离保养的里程数";
CM_ SG_ 1305 Maintenance_daysInfo "The days distance of Maintenance
距离保养的天数";
CM_ SG_ 1305 Maintenancealert "The sign of Maintenance alert 
保养提醒的标志";
CM_ SG_ 1305 OtaUpdataQuery "用户通过仪表选择升级查询，传递给TBOX检查是否有更新";
CM_ SG_ 1305 MFSStatu "平均能耗复位请求";
CM_ SG_ 1305 DriverModeSet "驾驶模式开关状态";
CM_ SG_ 1305 BrkBkEgyReq "滑行能量回收设置开关，记忆用户的设置";
CM_ SG_ 1305 StrModeSelect "转向助力模式设置";
CM_ SG_ 1305 TABButtonReq "坦克掉头模式";
CM_ SG_ 1305 PButtonReq "驻车软开关请求";
CM_ SG_ 1305 VSPswich "VSP开关请求";
CM_ SG_ 1305 OtaFeedback "用户反馈";
CM_ SG_ 1026 ICM_NM_DestAdd "OSEK network managament destination address";
CM_ SG_ 1026 ICM_NM_Alive "OSKE network managament alive signal";
CM_ SG_ 1026 ICM_NM_Ring "OSKE network managament Ring signal";
CM_ SG_ 1026 ICM_NM_LimpHome "OSKE network managament limp home signal";
CM_ SG_ 1026 ICM_NM_SleepInd "OSKE network managament bus sleep indication signal";
CM_ SG_ 1026 ICM_NM_SleepAck "OSKE network managament bus sleep acknowledge  signal";
CM_ SG_ 1408 GPSTimeMonth "Month value of current time";
CM_ SG_ 1408 GPSTimeYear "Year value of current time";
CM_ SG_ 1408 GPSTimeDay "Day value of current time";
CM_ SG_ 1408 GPSTimeHour "Hour value of current time";
CM_ SG_ 1408 GPSTimeMinute "Minute value of current time";
CM_ SG_ 1408 GPSTimeSecond "Second vlaue of current time";
CM_ SG_ 1408 TimeDisPlayFormat "Time Display Format时间显示格式";
CM_ SG_ 1411 LightDelayOutSet "外部灯光延时时间设置";
CM_ SG_ 1411 LightDelayInSet "内部灯光延时时间设置";
CM_ SG_ 1411 HornAlertVolumeSet "Horn alert volume
设防提示音量大小";
CM_ SG_ 1411 SpeedLockValueSet "automatic lock when the car speed is over threshold speed value
自动车速锁设置";
CM_ SG_ 1411 WinDownByKeySet "windows automatic down by remote key
遥控自动降窗开启/关闭";
CM_ SG_ 1411 AssistLightStateSet "assistant illumination by fog lamp when turing
转向辅助照明开启/关闭（开前雾灯）";
CM_ SG_ 1411 WinCloseRainEnableSet "Functional switch for Auto Closings Windows in rain
雨天自动关窗";
CM_ SG_ 1525 HU_TBOX_WiFi_Req "HU向TBOX请求WiFi连接";
CM_ SG_ 1525 HU_TBOX_SN_Req "HU向TBOX请求SN";
CM_ SG_ 1525 HU_TBOX_VIN_Req "HU向TBOX请求VIN";
CM_ SG_ 1028 HU_NM_DestAdd "OSKE network managament destination address";
CM_ SG_ 1028 HU_NM_Alive "OSKE network managament alive signal";
CM_ SG_ 1028 HU_NM_Ring "OSKE network managament Ring signal";
CM_ SG_ 1028 HU_NM_LimpHome "OSKE network managament limp home signal";
CM_ SG_ 1028 HU_NM_SleepInd "OSKE network managament bus sleep indication signal";
CM_ SG_ 1028 HU_NM_SleepAck "OSKE network managament bus sleep acknowledge  signal";
CM_ SG_ 865 Win_Position_RSD_FL "Window position";
CM_ SG_ 865 Win_Position_RSD_FR "Window position";
CM_ SG_ 865 Win_Position_RSD_RL "Window position";
CM_ SG_ 865 Win_Position_RSD_RR "Window position";
CM_ SG_ 865 PowerWindowPinchProtectionAlarm "Window Up Alarm state";
CM_ SG_ 865 RearWindowSuppressionStatus "Window suppression SW state";
CM_ SG_ 865 RemoteOpenWindow "反馈是否执行开启车窗";
CM_ SG_ 865 RemoteCloseWindow "反馈是否执行关闭车窗";
CM_ SG_ 865 APMConditionNotCorrect "反馈未执行远程指令时条件不满足的原因";
CM_ SG_ 691 LDW_Warning "Lane Departure Warning Status";
CM_ SG_ 691 FCW_Warning "Forward Collision Warning Status ";
CM_ SG_ 691 camera_status " camera status";
CM_ SG_ 691 LDW_Status "Lane Departure and Forward Collision System Status  ";
CM_ SG_ 691 FCW_Status "Forward Collision System Status  ";
CM_ SG_ 691 FCW_Button "LDFC Hard Button Switch";
CM_ SG_ 691 LDWSResp "LDWS systerm response  to DVD";
CM_ SG_ 691 FCWResp "FCW systerm response  to DVD";
CM_ SG_ 691 LDFC_NotWarning1 "LDFC Not Warning Status";
CM_ SG_ 691 LDFC_NotWarning2 "LDFC Not Warning Status";
CM_ SG_ 691 LDFC_NotWarning3 "LDFC Not Warning Status";
CM_ SG_ 691 LDFC_NotWarning4 "LDFC Not Warning Status";
CM_ SG_ 691 LDFC_NotWarning5 "LDFC Not Warning Status";
CM_ SG_ 691 LDFC_NotWarning6 "LDFC Not Warning Status";
CM_ SG_ 691 LeftLaneTrack "Lane Tracking Status,Left 
左边检测线";
CM_ SG_ 691 RightLaneTrack "Lane Tracking Status,Right
右侧检测线";
CM_ SG_ 691 RightLaneDistance "Lane Departure Distance, Right Side   右侧车道偏离距离";
CM_ SG_ 691 LeftLaneDistance "Lane Departure Distance, Left Side    左侧车道偏离距离";
CM_ SG_ 691 FrontObstacleDistance "Obstacle distance,Front Side正面障碍物距离";
CM_ SG_ 1429 Year_TCO "年";
CM_ SG_ 1429 Mon_TCO "月";
CM_ SG_ 1429 Date_TCO "日";
CM_ SG_ 1429 Hour_TCO "时";
CM_ SG_ 1429 Mint_TCO "分";
CM_ SG_ 1429 Sec_TCO "秒";
CM_ SG_ 1429 TimTyp_TCO "数据类型";
CM_ SG_ 1520 tbDoorCtrlReq "TBOX Request Door control progress";
CM_ SG_ 1520 tbFindCarReq "TBOX Request start Find Car progress";
CM_ SG_ 1520 tbWindowCtrlReq "TBOX Request Window control progress";
CM_ SG_ 1520 tbWinPosCtrlReqFL "Position_Req";
CM_ SG_ 1520 tbWinPosCtrlReqFR "Position_Req";
CM_ SG_ 1520 TelemaStatus "TBOX Telematics Status";
CM_ SG_ 1520 UpgradeSta "升级状态";
CM_ SG_ 1521 OtaUpdateTime "预计升级时间";
CM_ SG_ 1521 OtaUpdateProgress "OTA安装进度";
CM_ SG_ 1521 OtaUpdateNotify "更新提示";
CM_ SG_ 1521 OtaUpdateState "升级条件";
CM_ SG_ 1521 OtaUpdateResult "安装结果";
CM_ SG_ 1524 WiFiInfo "TBOX回复WiFi名称和密码给DVR";
CM_ SG_ 1529 TBOX_SN "TBOX回复SN码";
CM_ SG_ 1530 TBOX_VIN "TBOX回复VIN码";
CM_ SG_ 1037 TBOX_NM_DestAdd "OSKE network managament destination address";
CM_ SG_ 1037 TBOX_NM_Alive "OSKE network managament alive signal";
CM_ SG_ 1037 TBOX_NM_Ring "OSKE network managament Ring signal";
CM_ SG_ 1037 TBOX_NM_LimpHome "OSKE network managament limp home signal";
CM_ SG_ 1037 TBOX_NM_SleepInd "OSKE network managament bus sleep indication signal";
CM_ SG_ 1037 TBOX_NM_SleepAck "OSKE network managament bus sleep acknowledge  signal";
CM_ SG_ 1413 OneHourWakeupflag "1H唤醒标志位";
CM_ SG_ 1413 Year "年";
CM_ SG_ 1413 Mon "月";
CM_ SG_ 1413 Date "日";
CM_ SG_ 1413 Hour "时";
CM_ SG_ 1413 Mint "分";
CM_ SG_ 1413 Sec "秒";
CM_ SG_ 1413 TimTyp "数据类型";
CM_ SG_ 1413 TBOXDTC "故障码";
CM_ SG_ 1672 LocationVd "定位状态";
CM_ SG_ 1672 LatitudeDir "纬度方向";
CM_ SG_ 1672 LongitudeDir "经度方向";
CM_ SG_ 1672 GPSSpd "速度";
CM_ SG_ 1672 GPSDirection "方向";
CM_ SG_ 1673 GPSLongitude "经度";
CM_ SG_ 1673 GPSLatitude "纬度";
CM_ SG_ 1532 RmtACReq "远程空调请求";
CM_ SG_ 1532 RmtChgReq "远程充电请求";
CM_ SG_ 1532 LVBChgCmd "智能补电充电请求";
CM_ SG_ 1532 MPPreHeatMode "手机预加热模式选择，高档低档";
CM_ SG_ 1532 RmtACReqTpt "远程空调需求温度";
CM_ SG_ 279 VCU_117Counter "消息计数器";
CM_ SG_ 279 CruSysSet "
巡航功能激活状态";
CM_ SG_ 279 CruSysOn "巡航主开关状态";
CM_ SG_ 279 BrkPdlPsnVd "制动开关信号有效位";
CM_ SG_ 279 MCU1_MotorRPM "驱动电机_电机转速";
CM_ SG_ 279 BrkPdlPsnNC "刹车踏板常闭开关状态";
CM_ SG_ 279 BrkPdlPsnNO "
刹车踏板常开开关状态-制动灯开关";
CM_ SG_ 279 GasPdlPsnVd "
加速踏板开度有效位";
CM_ SG_ 279 VCU_EngSt1CheckSum "checksum";
CM_ SG_ 279 GasPdlPsnRaw "真实加速踏板开度";
CM_ SG_ 600 VCU_EngSt2MsgCounter "消息计数器";
CM_ SG_ 600 Ready "运行状态";
CM_ SG_ 600 VCUKeySta "钥匙状态
0x0:OFF&ACC档
0x1:ON档，车辆未进入READY状态
0x2:车辆的进行READY状态";
CM_ SG_ 600 GearPsn "档位";
CM_ SG_ 600 IMMOFeedback "IMMO认证反馈";
CM_ SG_ 600 DriveModelFd "驾驶模式";
CM_ SG_ 600 HVACPowerlimit "空调系统功率限制";
CM_ SG_ 600 VacuumPressureVd "制动真空度有效位";
CM_ SG_ 600 VacuumPressure "制动真空度信号";
CM_ SG_ 600 CruVehSpdVd "车辆巡航速度有效位";
CM_ SG_ 600 HVACHVforbidden "空调系统高压禁止";
CM_ SG_ 600 BrkBkEgyFd "滑行能量回收设置反馈";
CM_ SG_ 600 VCUBrakelightReq "点亮制动灯请求";
CM_ SG_ 600 CruVehSpd "车辆巡航速度";
CM_ SG_ 825 VCU_339sgCounter "Rolling counter信号，每个发送周期加1，循环计数，0到15循环";
CM_ SG_ 825 VCU_339Checksum "按照JAC checksum规范";
CM_ SG_ 825 OptPow "功率数值";
CM_ SG_ 825 HVBTpt "电池温度";
CM_ SG_ 825 HVBSOCI "电池SOC";
CM_ SG_ 825 EgyFlowSta "能量流状态";
CM_ SG_ 825 ReadyInd "READY指示灯";
CM_ SG_ 825 ChgLineInd "充电线连接指示灯";
CM_ SG_ 825 TMFltInd "电机故障警示灯";
CM_ SG_ 825 LVBFltInd "12V电池故障警示灯";
CM_ SG_ 825 VCUFltInd "系统故障警示灯";
CM_ SG_ 825 SOCLowInd "低电荷报警（仪表接收）";
CM_ SG_ 825 HVBFltInd "动力电池故障警示灯";
CM_ SG_ 825 lmtPowInd "限功率指示灯";
CM_ SG_ 825 ChgStsInd "充电状态指示灯";
CM_ SG_ 825 HVBCutInd "动力电池切断指示灯";
CM_ SG_ 595 VCU_253MsgCounter "Rolling counter信号，每个发送周期加1，循环计数，0到15循环";
CM_ SG_ 595 RemKm_Vd "续航里程有效位";
CM_ SG_ 595 InsEgyConsptChangeFlg "瞬时能耗数值改变提示标志位";
CM_ SG_ 595 AvgEgyConspt "平均能耗";
CM_ SG_ 595 InsEgyConspt "瞬时能耗:";
CM_ SG_ 595 AvgConsptModeFd "平均能耗用户选择按钮反馈";
CM_ SG_ 595 RemKm "综合续航里程（CLTC标准续驶里程）";
CM_ SG_ 595 VCU_253Checksum "按照JAC checksum规范";
CM_ SG_ 1093 VCUTxt "仪表显示信息";
CM_ SG_ 1093 PCUEgyConspt "电驱动消耗能量";
CM_ SG_ 1093 ACEgyConspt "空调开启消耗能量:";
CM_ SG_ 1093 BrkBkEgy "能量回收装置回收的能量:";
CM_ SG_ 1093 AllEgyConspt "总消耗能量";
CM_ SG_ 1093 HVBSOH "电池SOH
转发BMS的SOH信号";
CM_ SG_ 1140 ChgRemTim "电量充满剩余时间（h）
根据慢充或快充的充电电流和SOC状态，计算出充满剩余时间。";
CM_ SG_ 1140 PlugSts "充电插头状态";
CM_ SG_ 1140 ChgSta "充电标志位";
CM_ SG_ 1140 TmgTimesetFlagFDMP5 "定时充电设置标志位反馈(MP5)";
CM_ SG_ 1140 TmgChgShowFB "0:初始值； 1:按钮显示开始充电（用户点击时发送TmgUserReqtmgEnd==1）；2:按钮显示停止充电（用户点击时发送TmgUserReqtmgEnd==2）Tmgchg保持发送 10s";
CM_ SG_ 1140 CAN_VCU_MP5_CHR_DISSATISFY "充电条件不满足";
CM_ SG_ 1140 CAN_VCU_MP5_LTPROHB "禁止低温充电提示";
CM_ SG_ 1140 ChgStart "充电开始";
CM_ SG_ 1140 CAN_VCU_MP5_CHR_MODE "充电模式信息";
CM_ SG_ 1140 EgyFull "电量已充满语句";
CM_ SG_ 612 ACONRemKm "AC开启剩余里程";
CM_ SG_ 612 ACOFFRemKm "AC关闭剩余里程";
CM_ SG_ 612 VCU_Voltage "整车电压，未上高压发送0xFFFF";
CM_ SG_ 612 VCU_Current "电池电流，未上高压发送0xFFFF";
CM_ SG_ 430 ESC_VehSpdCheckSum "Message CheckSum";
CM_ SG_ 430 ABSItvInProgress "ABS功能执行";
CM_ SG_ 430 AYCItvInProgress "AYC功能执行";
CM_ SG_ 430 TCSItvInProgress "TCS功能执行";
CM_ SG_ 430 EBDitvinprogress "EBD功能执行";
CM_ SG_ 430 ESC_VehSpdCounter "Message counter";
CM_ SG_ 430 VehSpdVd "车速值有效位";
CM_ SG_ 430 VehSpd "车速值";
CM_ SG_ 430 EngTqIncReqAct "
ESC增扭请求有效性";
CM_ SG_ 430 ABSWarningLamp "ABS故障灯";
CM_ SG_ 430 ESC_SYS_WarnLamp_EDR "ESC故障灯";
CM_ SG_ 430 EngTqIncReq "
ESC增扭请求";
CM_ SG_ 430 EngTqDecReqAct "ESC降扭请求有效性";
CM_ SG_ 430 EBDWarningLamp "EBD故障灯";
CM_ SG_ 430 EngTqDecReqFast "
ESC降扭请求";
CM_ SG_ 517 YawRate "横摆角速度";
CM_ SG_ 517 LongAccVd "
纵向加速度有效位";
CM_ SG_ 517 HDCStatus "HDC工作状态";
CM_ SG_ 517 YawRateVd "横摆角速度有效位";
CM_ SG_ 517 LongAcc "纵向加速度";
CM_ SG_ 517 AYCFailure "AYC故障";
CM_ SG_ 517 EBDFailure "EBD故障";
CM_ SG_ 517 ABSFailure "ABS故障";
CM_ SG_ 517 TCSFailure "CS故障";
CM_ SG_ 517 GearShiftForbidden "Gear shift forbidden request from ESC to TCU请求禁止换挡";
CM_ SG_ 517 ESC_AccelStaCheckSum "Message CheckSum";
CM_ SG_ 517 BrkPrsVd "刹车压力有效位";
CM_ SG_ 517 ESC_AccelStaCounter "Message counter";
CM_ SG_ 517 BrkPrs "刹车压力";
CM_ SG_ 533 ESC_ESCStCheckSum "Message CheckSum";
CM_ SG_ 533 ESCSw "ESC系统状态";
CM_ SG_ 533 ESCSwVd "ESC系统状态有效位";
CM_ SG_ 533 ESC_ESCStCounter "Message counter";
CM_ SG_ 533 AutoHoldActive "AutoHold功能执行";
CM_ SG_ 533 AutoHoldAvailable "AutoHold功能可用";
CM_ SG_ 533 AutoholdFailure " AutoHold功能故障";
CM_ SG_ 533 HSAActive "HA Active  ";
CM_ SG_ 533 HSAFailure "HA Failure  ";
CM_ SG_ 533 AutoHazardBlinking "自动危险警示灯闪烁";
CM_ SG_ 533 GSensorCalibrationSt "G-sensorCalibration_status";
CM_ SG_ 533 AutoHoldSWStsVd " AutoHold开关状态有效性";
CM_ SG_ 533 AutoHoldSWSts " AutoHold开关状态";
CM_ SG_ 533 LatAccVd "横向加速度有效位";
CM_ SG_ 533 LatAcc "横向加速度";
CM_ SG_ 675 EPSFailure "EPS故障状态";
CM_ SG_ 675 EPS_StrModeFeedback "Feedback current EPS mode to ICM
反馈EPS当前模式给ICM";
CM_ SG_ 675 EPS_TorqSensorStatus "扭矩传感器状态";
CM_ SG_ 675 EPS_CurrentConsumption " 电流消耗";
CM_ SG_ 675 EPS_SteeringTorque "转向扭矩";
CM_ SG_ 675 EPSSWVer "软件版本号";
CM_ SG_ 675 EPSHWVer "硬件版本号";
CM_ SG_ 675 EPSDTC "EPS故障码";
CM_ SG_ 309 EPS_SASChecksum "信号表示消息校验和";
CM_ SG_ 309 EPS_SASMsgCounter "信号表示EPS的消息计数器";
CM_ SG_ 309 SAS_FailureSts "方向盘转角传感器信号错误标志";
CM_ SG_ 309 SAS_CalibrationSts "方向盘转角标定位";
CM_ SG_ 309 SteeringWheelAngle "实际方向盘转向角  顺时针>0 ,逆时针<0";
CM_ SG_ 309 SteeringWheelRotSpd "方向盘转向角速度";
CM_ SG_ 309 SteeringWheelRotDir "方向盘转向角速度方向";
CM_ SG_ 125 AirbagFailSts "安全气囊系统状态";
CM_ SG_ 125 CrashInfo "碰撞信号";
CM_ SG_ 125 SRS_StatusCheckSum "Message CheckSum";
CM_ SG_ 125 SRS_StatusCounter "The transmitter shall update the value of the Message Counter signal every time a frame is transmitted ";
CM_ SG_ 526 VehSpdVd "Vehicle speed valid";
CM_ SG_ 526 VehSpd "Vehicle speed";
CM_ SG_ 526 EBS_FaultSts "EBS故障状态";
CM_ SG_ 526 EPBSts "EPB状态";
CM_ SG_ 526 FailureLampSts "EPB故障灯状态";
CM_ SG_ 526 GearPsn_GW "档位";
CM_ SG_ 945 ModeDisp "空调工作模式显示";
CM_ SG_ 945 RmtACReqFb "远程空调反馈";
CM_ SG_ 945 HVAC_State "空调系统状态信号";
CM_ SG_ 945 SetTemDisp "温度设置显示";
CM_ SG_ 945 ExtTempVd "
外部温度";
CM_ SG_ 945 HVAC_RearDefrost "后除霜请求";
CM_ SG_ 945 BlowerLvl "
鼓风机档位";
CM_ SG_ 945 ExtTemp "
外部温度";
CM_ SG_ 947 IndicatorAutoFront "前自动模式指示灯";
CM_ SG_ 947 IndicatorDefrostFront "前除霜指示灯";
CM_ SG_ 947 IndicatorACFront "前面板AC请求指示灯";
CM_ SG_ 947 IndicatorOFFFront "前空调关闭指示灯";
CM_ SG_ 947 IndicatorIntakeFront "前外循环指示灯";
CM_ SG_ 947 InternalRecycle "内循环指示灯";
CM_ SG_ 947 HURequest "DVD/HU显示请求";
CM_ SG_ 947 HUCancel "DVD/HU显示请求取消";
CM_ SG_ 914 ECSta "压缩机工作状态";
CM_ SG_ 914 ECSts "系统正常";
CM_ SG_ 914 ECost "压缩机限功率运行标志位";
CM_ SG_ 914 ECSWVerY "软件版本号年";
CM_ SG_ 914 ECSWVerM "软件版本号月";
CM_ SG_ 914 ECSWVerD "软件版本号日";
CM_ SG_ 914 ECHWVer "硬件版本号";
CM_ SG_ 914 ECDTC "故障码";
CM_ SG_ 1077 ACPTCPwrReq "PTC功率反馈";
CM_ SG_ 1077 PTCTpt "PTC温度反馈";
CM_ SG_ 1077 PTCRly1Ctl "PTC继电器1空调";
CM_ SG_ 1077 PTCRly2Ctl "PTC2继电器空调";
CM_ SG_ 1084 ACDCT "空调故障码";
CM_ SG_ 1290 ParkWarnStatus_L "Park warning  status of the left BSD
左雷达开门告警功能报警状态";
CM_ SG_ 1290 LCMAStatus_L "Blind spot detection alarm status of the left BSD
左雷达换道辅助功能报警状态";
CM_ SG_ 1290 CrossTrafficAlertSt_L "Cross traffic alert  status  of the left BSD
左雷达倒车辅助告警功能报警功能";
CM_ SG_ 1290 BlindSpotDetectionStayus_L "Blind Spot Detection status  of the left BSD
左雷达盲点监测报警状态";
CM_ SG_ 1290 BSDSysStatus "System status
系统状态";
CM_ SG_ 1290 DOW_Status "DOW Function status
DOW功能状态";
CM_ SG_ 1290 BSD_Status "BSD Function status
BSD功能状态";
CM_ SG_ 1290 LCA_Status "LCA Function status
LCA功能状态";
CM_ SG_ 1290 RCTA_Status "RCTA Function status
RCTA功能状态";
CM_ SG_ 704 ParkWarnStatus_R "Park warning  status of the right BSD
右雷达开门告警功能报警状态";
CM_ SG_ 704 LCMAStatus_R "Lane change merge assist  alarm status  of the right BSD
右雷达换道辅助功能报警状态";
CM_ SG_ 704 CrossTrafficAlertSt_R "Cross traffic alert  status  of the right  BSD
右雷达倒车辅助告警功能报警功能";
CM_ SG_ 704 BlindSpotDetectionStayus_R "Rear collision warning status  of the right BSD
右雷达盲点监测报警状态";
CM_ SG_ 704 BSDSysStatus "System status
系统状态";
CM_ SG_ 704 DOW_Status "DOW Function status
DOW功能状态";
CM_ SG_ 704 BSD_Status "BSD Function status
BSD功能状态";
CM_ SG_ 704 LCA_Status "LCA Function status
LCA功能状态";
CM_ SG_ 704 RCTA_Status "RCTA Function status
RCTA功能状态";
CM_ SG_ 915 Year_WS "年";
CM_ SG_ 915 Mon_WS "月";
CM_ SG_ 915 Date_WS "日";
CM_ SG_ 915 Hour_WS "时";
CM_ SG_ 915 Mint_WS "分";
CM_ SG_ 915 Sec_WS "秒";
CM_ SG_ 915 AEBS_Status_WS "AEBS状态";
CM_ SG_ 915 AEBS_ActiveState_WS "AEBS响应状态";
CM_ SG_ 915 VehicleSpeed_WS "Vehicle speed  ";
CM_ SG_ 915 YawRate_WS "The angular velocity of the vehicle about the z:axis (rotation speed about the cg of the vehicle). Required for VDC functionality";
CM_ SG_ 915 AccelPedalposition_WS "Actual gas pedal position of the vehicle: if the Cruise function active: this signal is the fictitious gas pedal position.";
CM_ SG_ 915 BrakePedalSwitchStatus_WS "Brake padel position (normal close),When Brake padel pressed this signal is 1,else is 0";
CM_ SG_ 916 Year_WD "年";
CM_ SG_ 916 Mon_WD "月";
CM_ SG_ 916 Date_WD "日";
CM_ SG_ 916 Hour_WD "时";
CM_ SG_ 916 Mint_WD "分";
CM_ SG_ 916 Sec_WD "秒";
CM_ SG_ 916 AEBS_Status_WD "AEBS状态";
CM_ SG_ 916 AEBS_ActiveState_WD "AEBS响应状态";
CM_ SG_ 916 VehicleSpeed_WD "Vehicle speed  ";
CM_ SG_ 916 YawRate_WD "The angular velocity of the vehicle about the z:axis (rotation speed about the cg of the vehicle). Required for VDC functionality";
CM_ SG_ 916 AccelPedalposition_WD "Actual gas pedal position of the vehicle: if the Cruise function active: this signal is the fictitious gas pedal position.";
CM_ SG_ 916 BrakePedalSwitchStatus_WD "Brake padel position (normal close),When Brake padel pressed this signal is 1,else is 0";
CM_ SG_ 917 Year_BS "年";
CM_ SG_ 917 Mon_BS "月";
CM_ SG_ 917 Date_BS "日";
CM_ SG_ 917 Hour_BS "时";
CM_ SG_ 917 Mint_BS "分";
CM_ SG_ 917 Sec_BS "秒";
CM_ SG_ 917 AEBS_Status_BS "AEBS状态";
CM_ SG_ 917 AEBS_ActiveState_BS "AEBS响应状态";
CM_ SG_ 917 VehicleSpeed_BS "Vehicle speed  ";
CM_ SG_ 917 YawRate_BS "The angular velocity of the vehicle about the z:axis (rotation speed about the cg of the vehicle). Required for VDC functionality";
CM_ SG_ 917 AccelPedalposition_BS "Actual gas pedal position of the vehicle: if the Cruise function active: this signal is the fictitious gas pedal position.";
CM_ SG_ 917 BrakePedalSwitchStatus_BS "Brake padel position (normal close),When Brake padel pressed this signal is 1,else is 0";
CM_ SG_ 918 Year_BD "年";
CM_ SG_ 918 Mon_BD "月";
CM_ SG_ 918 Date_BD "日";
CM_ SG_ 918 Hour_BD "时";
CM_ SG_ 918 Mint_BD "分";
CM_ SG_ 918 Sec_BD "秒";
CM_ SG_ 918 AEBS_Status_BD "AEBS状态";
CM_ SG_ 918 AEBS_ActiveState_BD "AEBS响应状态";
CM_ SG_ 918 VehicleSpeed_BD "Vehicle speed  ";
CM_ SG_ 918 YawRate_BD "The angular velocity of the vehicle about the z:axis (rotation speed about the cg of the vehicle). Required for VDC functionality";
CM_ SG_ 918 AccelPedalposition_BD "Actual gas pedal position of the vehicle: if the Cruise function active: this signal is the fictitious gas pedal position.";
CM_ SG_ 918 BrakePedalSwitchStatus_BD "Brake padel position (normal close),When Brake padel pressed this signal is 1,else is 0";
CM_ SG_ 919 AEBStatus "Request of the Prefill to ESP.";
CM_ SG_ 919 LineRightWarning "右车道偏离报警";
CM_ SG_ 919 LineLeftWarning "左车道偏离报警";
CM_ SG_ 919 FCWWarning "前碰撞报警";
CM_ SG_ 919 SensorStatus "传感器状态";
CM_ SG_ 919 LDWStatus "车道偏离系统状态";
CM_ SG_ 919 LineLeft_Type "左侧车道线类型";
CM_ SG_ 919 LineRight_Type "右侧车道线类型";
CM_ SG_ 500 BSD_FUNCTION_SW "BSD System On/Off Switch
盲点监测系统开关";
CM_ SG_ 500 Poslamp "
位置灯状态";
CM_ SG_ 500 Trunk_BackDoor_Sts "尾门/后备箱门状态";
CM_ SG_ 500 PsgDoorStatus "右前门状态";
CM_ SG_ 500 RRDoorStatus "右后门状态";
CM_ SG_ 500 RLDoorStatus "左后门状态";
CM_ SG_ 500 DRVUnlockState "左前门锁状态";
CM_ SG_ 500 DefrostCtrl "后除霜状态";
CM_ SG_ 500 DrvDoorStatus "左前门状态";
CM_ SG_ 500 OccupantDetDRVSideVd "主驾安全带开关信号可信度";
CM_ SG_ 500 HeadLampLowBeamCtrl "前大灯近光控制";
CM_ SG_ 500 HeadLampHighBeamCtrl "前大灯远光控制";
CM_ SG_ 500 LDW_SWSet "LDW systerm set by DVD
LDW系统设置";
CM_ SG_ 500 KeyState_GW "点火钥匙状态";
CM_ SG_ 500 HoodStatus "引擎盖状态";
CM_ SG_ 500 OccupantDetDRVSide "驾驶员安全带状态";
CM_ SG_ 500 AEBSet "AEBS systerm set by DVD
AEBS系统设置";
CM_ SG_ 500 TurnSwitch_GW "转向开关状态";
CM_ SG_ 500 FrontWiperStatus_GW "前雨刮状态";
CM_ SG_ 500 DirIndicationLeft_GW "左转向灯状态，信号值变化和转向灯同频率";
CM_ SG_ 500 DirIndicationRight_GW "右转向灯状态，信号值变化和转向灯同频率";
CM_ SG_ 500 HazardWarningLightStatus "危险警告灯状态";
CM_ SG_ 500 BCM_KeyState_VD "KeyState信号有效标志位";
CM_ SG_ 500 Checksumof1F4 "Message CheckSum";
CM_ SG_ 500 TurnSwitchVd "转向开关状态有效位";
CM_ SG_ 500 Counterof1F4 "message counter ";
CM_ SG_ 500 StrModeSelect "转向助力模式设置";
CM_ SG_ 572 ESC_FWhlSpdCheckSum "Message CheckSum";
CM_ SG_ 572 ESC_FWhlSpdCounter "Message counter";
CM_ SG_ 572 WhlSpdFRVd "右前轮速有效位";
CM_ SG_ 572 WhlSpdFR "右前轮速";
CM_ SG_ 572 WhlSpdFLVd "左前轮速有效位";
CM_ SG_ 572 WhlSpdFL "左前轮速";
CM_ SG_ 573 ESC_RWhlSpdCheckSum "Message CheckSum";
CM_ SG_ 573 ESC_RWhlSpdCounter "Message counter";
CM_ SG_ 573 WhlSpdRRVd "右后轮速有效位";
CM_ SG_ 573 WhlSpdRR "右后轮速";
CM_ SG_ 573 WhlSpdRLVd "
左后轮速有效位";
CM_ SG_ 573 WhlSpdRL "左后轮速";
CM_ SG_ 810 ESC_WhlSpdDirCheckSum "Message CheckSum";
CM_ SG_ 810 FLWheelDir "左前轮转动方向";
CM_ SG_ 810 FRWheelDir "右前轮转动方向";
CM_ SG_ 810 RLWheelDir "左后轮转动方向";
CM_ SG_ 810 RRWheelDir "右后轮转动方向";
CM_ SG_ 810 ESC_WhlSpdDirCounter "Message counter";
CM_ SG_ 810 RRWheelSpdPulse "右后轮脉冲计数";
CM_ SG_ 810 RLWheelSpdPulse "右后轮脉冲计数";
CM_ SG_ 810 FRWheelSpdPulse "右前轮脉冲计数";
CM_ SG_ 810 FLWheelSpdPulse "左前轮脉冲计数";
CM_ SG_ 804 HVBOptPow "驱动瞬时功率";
CM_ SG_ 804 HVAvailablePower "驱动可用剩余功率";
CM_ SG_ 804 EgyRecycleOptPow "能量回收瞬时功率";
CM_ SG_ 804 EgyRecycleAvailablePower "能量回收可用剩余功率";
CM_ SG_ 809 RemKMAge_Dyn "WLTC动态续驶里程";
BA_DEF_  "DBName" STRING ;
BA_DEF_  "BusType" STRING ;
BA_DEF_  "BaudRate" FLOAT 1000 1000000;
BA_DEF_ BO_  "GenMsgSendType" ENUM  "cyclic","spontaneous","spontaneous","cyclicIfActive","spontaneousWithDelay";
BA_DEF_ BO_  "GenMsgCycleTime" FLOAT 0 300000;
BA_DEF_DEF_  "DBName" "";
BA_DEF_DEF_  "BusType" "";
BA_DEF_DEF_  "BaudRate" 500000;
BA_DEF_DEF_  "GenMsgSendType" "cyclic";
BA_DEF_DEF_  "GenMsgCycleTime" 0;
BA_ "BusType" "CAN";
BA_ "DBName" "E3_X6D12BCAN_V1_16_20250924";
BA_ "GenMsgCycleTime" BO_ 683 50;
BA_ "GenMsgCycleTime" BO_ 717 50;
BA_ "GenMsgCycleTime" BO_ 666 50;
BA_ "GenMsgCycleTime" BO_ 824 100;
BA_ "GenMsgCycleTime" BO_ 791 500;
BA_ "GenMsgCycleTime" BO_ 930 500;
BA_ "GenMsgSendType" BO_ 1025 1;
BA_ "GenMsgCycleTime" BO_ 1303 100;
BA_ "GenMsgCycleTime" BO_ 1304 100;
BA_ "GenMsgCycleTime" BO_ 1305 100;
BA_ "GenMsgSendType" BO_ 1026 1;
BA_ "GenMsgCycleTime" BO_ 1408 500;
BA_ "GenMsgCycleTime" BO_ 1411 50;
BA_ "GenMsgSendType" BO_ 1525 1;
BA_ "GenMsgSendType" BO_ 1028 1;
BA_ "GenMsgCycleTime" BO_ 865 100;
BA_ "GenMsgCycleTime" BO_ 691 50;
BA_ "GenMsgCycleTime" BO_ 1429 200;
BA_ "GenMsgCycleTime" BO_ 1520 100;
BA_ "GenMsgCycleTime" BO_ 1521 100;
BA_ "GenMsgSendType" BO_ 1524 1;
BA_ "GenMsgSendType" BO_ 1529 1;
BA_ "GenMsgSendType" BO_ 1530 1;
BA_ "GenMsgSendType" BO_ 1037 1;
BA_ "GenMsgCycleTime" BO_ 1413 200;
BA_ "GenMsgCycleTime" BO_ 1672 1000;
BA_ "GenMsgCycleTime" BO_ 1673 1000;
BA_ "GenMsgCycleTime" BO_ 1532 200;
BA_ "GenMsgCycleTime" BO_ 279 10;
BA_ "GenMsgCycleTime" BO_ 600 50;
BA_ "GenMsgCycleTime" BO_ 825 100;
BA_ "GenMsgCycleTime" BO_ 595 200;
BA_ "GenMsgCycleTime" BO_ 1093 200;
BA_ "GenMsgCycleTime" BO_ 1140 200;
BA_ "GenMsgCycleTime" BO_ 612 200;
BA_ "GenMsgCycleTime" BO_ 430 10;
BA_ "GenMsgCycleTime" BO_ 517 10;
BA_ "GenMsgCycleTime" BO_ 533 20;
BA_ "GenMsgCycleTime" BO_ 675 50;
BA_ "GenMsgCycleTime" BO_ 309 10;
BA_ "GenMsgCycleTime" BO_ 125 20;
BA_ "GenMsgCycleTime" BO_ 526 50;
BA_ "GenMsgCycleTime" BO_ 945 50;
BA_ "GenMsgCycleTime" BO_ 947 50;
BA_ "GenMsgCycleTime" BO_ 914 100;
BA_ "GenMsgCycleTime" BO_ 1077 50;
BA_ "GenMsgCycleTime" BO_ 1084 100;
BA_ "GenMsgCycleTime" BO_ 1290 50;
BA_ "GenMsgCycleTime" BO_ 704 50;
BA_ "GenMsgSendType" BO_ 915 1;
BA_ "GenMsgSendType" BO_ 916 1;
BA_ "GenMsgSendType" BO_ 917 1;
BA_ "GenMsgSendType" BO_ 918 1;
BA_ "GenMsgCycleTime" BO_ 919 50;
BA_ "GenMsgCycleTime" BO_ 500 10;
BA_ "GenMsgCycleTime" BO_ 572 10;
BA_ "GenMsgCycleTime" BO_ 573 10;
BA_ "GenMsgCycleTime" BO_ 810 20;
BA_ "GenMsgCycleTime" BO_ 804 100;
BA_ "GenMsgCycleTime" BO_ 809 200;
VAL_ 683 SecurityStatus 0 "Not defended" 1 "Defended" ;
VAL_ 683 SecurityAlarm 0 "OFF" 1 "ON" ;
VAL_ 683 DrvLockCommand 0 "no lock/unlock action" 1 "RKE Lock" 2 "Smart Entry Lock" 3 "Mechanical Lock" 4 "Centrol Lock" 5 "RKE Unlock" 6 "Smart Entry Unlock" 7 "mechanical Unlock" 8 "Centrol Unlock" 9 "Remote lock" 10 "Remote unlock" 13 "30s auto lock" ;
VAL_ 683 KSEnable 0 "Disable" 1 "Enable" ;
VAL_ 683 DRLLamp 0 "OFF" 1 "ON" ;
VAL_ 683 DayNightStatus 0 "Day" 1 "Night" ;
VAL_ 683 BCM_RemoteKeyID 0 "No ID detection" 1 "ID1" 2 "ID2" 3 "ID3" 4 "ID4" ;
VAL_ 683 BackLightControl 0 "OFF" 1 "Light with the backlight level" 2 "Light with the maximum backlight level " 3 "not used" ;
VAL_ 683 LockCtrl 0 " no lock/unlock action" 1 " any lock request different from RKE or Smart and relock" 33 " RKE lock ID No.1" 34 " RKE lock ID No.2" 35 " RKE lock ID No.3" 36 " RKE lock ID No.4" 47 " RKE 30s autolock" 63 " Smart 30s autolock" 49 " Smart Entry lock ID No.1" 50 " Smart Entry lock ID No.2" 51 " Smart Entry lock ID No.3" 52 " Smart Entry lock ID No.4" 65 "Auto Window Up" 129 " any unlock request different from RKE and Smart" 161 " RKE unlock ID No.1" 162 " RKE unlock ID No.2" 163 " RKE unlock ID No.3" 164 " RKE unlock ID No.4" 177 " Smart Entry unlock ID No.1" 178 " Smart Entry unlock ID No.2" 179 " Smart Entry unlock ID No.3" 180 " Smart Entry unlock ID No.4" 193 "Auto Window down" ;
VAL_ 683 DirIndicationLeft 0 "OFF" 1 "ON" ;
VAL_ 683 DirIndicationRight 0 "OFF" 1 "ON" ;
VAL_ 683 TurnSwitch 0 " OFF" 1 " Left" 2 " Right" 3 " Error" ;
VAL_ 683 HandBrakingStatus 0 "Release" 1 "Braking" ;
VAL_ 683 KeyState 0 "OFF" 1 "ACC" 2 "IGN" 3 "CRANK+IG" 7 "error" ;
VAL_ 683 BCM_KeyState_VD 0 "Inalid" 3 "Valid" ;
VAL_ 683 TurnSwitchVd 0 " not valid" 1 " valid" ;
VAL_ 683 WiperStatus 0 "wiper  off" 1 "Wiper  low " 2 "Wiper   high " ;
VAL_ 717 HazardWarningLightStatus 0 "OFF" 1 "ON" ;
VAL_ 717 RearWiperCtrl 0 "wiper  off" 1 "Wiper  low " 2 "Wiper   high " 3 "Wiper Relay Circuit Error" ;
VAL_ 717 FrontWindscreenWashSW 0 "OFF" 1 "ON" ;
VAL_ 717 FrontWiperIntAutoSW 0 "OFF" 1 "ON" ;
VAL_ 717 KeyInHoleStatus 0 "False" 1 "True" ;
VAL_ 717 AutoLightSW 0 "OFF" 1 "ON" ;
VAL_ 717 BCM_RemoteFeedback 0 "Nothing" 1 "Last remote ctr done" 2 "Auth failed" 3 "Condition error" 4 "Error" ;
VAL_ 717 BCM_RemoteAuthstate 0 "Default" 1 "RmtAuthOK" 2 "RmtAuthNotOK" 3 "Invalid" ;
VAL_ 717 FLWindowStatus 0 "off(close)" 1 "on(open)" ;
VAL_ 717 FRWindowStatus 0 "off(close)" 1 "on(open)" ;
VAL_ 717 RLWindowStatus 0 "off(close)" 1 "on(open)" ;
VAL_ 717 RRWindowStatus 0 "off(close)" 1 "on(open)" ;
VAL_ 717 KickSNRReq 1 "active request" 0 "not request" ;
VAL_ 717 SRF_PosStatus 0 "Fully Closed" 1 "Slide Open" 2 "Tilt Up" 3 "Opening" 4 "Closing" 5 "Reversing" 6 "Position not Trusted" ;
VAL_ 717 BCM_FrontWiperSW 0 "wiper  off" 1 "Wiper  low " 2 "Wiper   high " 3 "Wiper  int" 4 "Wiper auto" ;
VAL_ 717 Poslamp 0 "OFF" 1 "ON" ;
VAL_ 717 Trunk_BackDoor_Sts 0 "close" 1 "open" ;
VAL_ 717 HoodStatus 0 "off" 1 "on(open)" ;
VAL_ 717 HeadLampHighBeamCtrl 0 "OFF" 1 "ON" ;
VAL_ 717 FrontFogLamp 0 "OFF" 1 "ON" ;
VAL_ 717 DRVUnlockState 0 "lock" 1 "unlock" ;
VAL_ 717 HeadLampLowBeamCtrl 0 "OFF" 1 "ON" ;
VAL_ 717 DrvDoorStatus 0 "close" 1 "open" ;
VAL_ 717 PsgDoorStatus 0 "close" 1 "open" ;
VAL_ 717 RRDoorStatus 0 "close" 1 "open" ;
VAL_ 717 RLDoorStatus 0 "close" 1 "open" ;
VAL_ 717 DefrostCtrl 0 "OFF" 1 "ON" ;
VAL_ 717 RearFogLamp 0 "OFF" 1 "ON" ;
VAL_ 717 LeftSeatHeatCtrl 0 "OFF" 1 "ON" ;
VAL_ 717 RightSeatHeatCtrl 0 "OFF" 1 "ON" ;
VAL_ 666 LightDelayOutResp 0 "0s" 1 "30s" 2 "60s" 3 "90s" 4 "120s" ;
VAL_ 666 LightDelayInResp 0 "0s" 1 "15s" 2 "30s" 3 "45s" 4 "60s" ;
VAL_ 666 HornAlertVolumeResp 0 "Normal" 1 "High" 2 "Low" 3 "OFF" ;
VAL_ 666 SpeedLockValueResp 0 "40km/h Lock" 1 "15km/h Lock" 2 "OFF" ;
VAL_ 666 WindowRemoteAutoDownStateResp 0 "OFF" 1 "ON" ;
VAL_ 824 WR_status_FL 0 "Stop" 1 "Window Up (Include anti-pinch reversal)" 2 "Window Down" ;
VAL_ 824 WR_status_FR 0 "Stop" 1 "Window Up (Include anti-pinch reversal)" 2 "Window Down" ;
VAL_ 824 WR_status_RL 0 "Stop" 1 "Window Up (Include anti-pinch reversal)" 2 "Window Down" ;
VAL_ 824 WR_status_RR 0 "Stop" 1 "Window Up (Include anti-pinch reversal)" 2 "Window Down" ;
VAL_ 824 PowerWindowPinchProtectionAlarm 0 "Default" 1 "Window Up Alarm" ;
VAL_ 824 RemoteOpenWindow 0 "None Order" 1 "Executing" 2 "Implement" 3 "Implement fail" ;
VAL_ 824 RemoteSearch 0 "None Order" 1 "Executing" 2 "Implement" 3 "Implement fail" ;
VAL_ 824 RemoteLock 0 "None Order" 1 "Executing" 2 "Implement" 3 "Implement fail" ;
VAL_ 824 RemoteUnlock 0 "None Order" 1 "Executing" 2 "Implement" 3 "Implement fail" ;
VAL_ 824 RemoteCloseWindow 0 "None Order" 1 "Executing" 2 "Implement" 3 "Implement fail" ;
VAL_ 824 RemoteTrunkUnlock 0 "None Order" 1 "Executing" 2 "Implement" 3 "Implement fail" ;
VAL_ 824 BCMComStatus 0 "Normal" 1 "Not normal" ;
VAL_ 824 SecondLock 0 "Not Implement" 1 "Implement" ;
VAL_ 824 BCMConditionNotCorrect 0 "None（default）" 1 "配置字无效" 2 "点火档位不满足条件" 3 "电压低于9V后进入了电源管理模式后" 4 "车窗使能信号为enable" 5 "防夹通讯故障" 6 "触发防夹或未升到顶" 7 "遥控信号中断" 8 "左前门打开，上锁失败" 9 "有门打开，设防失败" 10 "30s内未收到尾门打开信号" ;
VAL_ 824 RemoteCloseSunRoof 0 "None Order" 1 "Executing" 2 "Implement" 3 "Implement fail" ;
VAL_ 791 FLPressureWarning 0 "No warning." 1 "No Sensor" 2 "Quik leakage. " 3 "High pressure warning. " 4 "Low pressure warning. " 5 "Sensor battery low" 6 "Sensor failure" ;
VAL_ 791 FRPressureWarning 0 "No warning. " 1 "No Sensor" 2 "Quik leakage. " 3 "High pressure warning. " 4 "Low pressure warning. " 5 "Sensor battery low" 6 "Sensor failure" ;
VAL_ 791 RLPressureWarning 0 "No warning." 1 "No Sensor " 2 "Quik leakage. " 3 "High pressure warning. " 4 "Low pressure warning. " 5 "Sensor battery low" 6 "Sensor failure" ;
VAL_ 791 RRPressureWarning 0 "No warning." 1 "No Sensor " 2 "Quik leakage. " 3 "High pressure warning. " 4 "Low pressure warning. " 5 "Sensor battery low" 6 "Sensor failure" ;
VAL_ 791 FLTempHigh 0 "No warning" 1 "High temperature warning" ;
VAL_ 791 FRTempHigh 0 "No warning" 1 "High temperature warning" ;
VAL_ 791 RLTempHigh 0 "No warning" 1 "High temperature warning" ;
VAL_ 791 RRTempHigh 0 "No warning" 1 "High temperature warning" ;
VAL_ 791 StudyMode 0 "Normal" 1 "studying TPMS" ;
VAL_ 791 SystemWarning 0 "No any error." 1 "System error." ;
VAL_ 791 StudyFailureWarning 0 "no failure" 1 "failure" ;
VAL_ 791 TireWarning 0 " no failure" 1 " failure" ;
VAL_ 1025 BCM_NM_Alive 0 "Node does not alive" 1 "Node alive" ;
VAL_ 1025 BCM_NM_Ring 0 "Ring not stable" 1 "Ring stable" ;
VAL_ 1025 BCM_NM_LimpHome 0 "Not in limp home" 1 "Limp home" ;
VAL_ 1025 BCM_NM_SleepInd 0 "Bus needed" 1 "Bus not need, requesr sleep" ;
VAL_ 1025 BCM_NM_SleepAck 0 "Network still alive" 1 "Network sleep acknowledge" ;
VAL_ 1303 OdometerInfoVd 0 "Not valid" 1 "Valid" ;
VAL_ 1303 ParkBrakeSW 0 "Release" 1 "Brake" ;
VAL_ 1303 BrakeFluidSW 0 "off, " 1 "on" ;
VAL_ 1303 OccupantDetDRVSideVd 0 "not valid" 1 "valid" ;
VAL_ 1303 ContryConfig 0 "China" 1 "Norty America" 2 "EU,AUS" 3 "EU DRL" 4 "GEN,MES" ;
VAL_ 1303 OccupantDetDRVSide 0 "unbelted" 1 "belted" ;
VAL_ 1303 UnitSet 0 "metric" 1 "imperial" ;
VAL_ 1304 LDW_SWSet_ICM 0 "LDWS  Disabled;" 1 "LDWS  Enabled;" ;
VAL_ 1304 AEBSet_ICM 0 "AEB  Disabled;" 1 "AEB  Enabled;" ;
VAL_ 1304 BSD_FUNCTION_SW 0 "Off" 1 "On" ;
VAL_ 1305 ICM_mode_status 0 "reserved " 1 "Classic " 2 "sport  " 3 "technology " ;
VAL_ 1305 Maintenancealert 0 "No maintain alert " 1 "Predicted maintain alert(距离保养里程≤200km,或距离保养天数≤5天）  " 2 "Immediately  maintain alert(距离保养里程0km,或距离保养天数0天）  " 3 "reserved" ;
VAL_ 1305 OtaUpdataQuery 0 "默认状态" 1 "升级查询" ;
VAL_ 1305 MFSStatu 0 "no request" 1 " request" ;
VAL_ 1305 DriverModeSet 0 "nomal" 1 "ECO" 2 "Sport" ;
VAL_ 1305 BrkBkEgyReq 0 "Normal" 1 "OFF" 2 "Low" 3 "High" ;
VAL_ 1305 StrModeSelect 0 "No request" 1 "Normal" 2 "Comfort" 3 "Sport" ;
VAL_ 1305 TABButtonReq 0 "TAB NotActive" 1 "TAB Active" 2 "Error" ;
VAL_ 1305 PButtonReq 0 "No request" 1 "Release Request" 2 "Apply Request" 3 "Error" ;
VAL_ 1305 VSPswich 0 "ON" 1 "OFF" ;
VAL_ 1305 OtaFeedback 0 "暂不更新" 1 "立即更新" ;
VAL_ 1026 ICM_NM_Alive 0 "Node does not alive" 1 "Node alive" ;
VAL_ 1026 ICM_NM_Ring 0 "Ring not stable" 1 "Ring stable" ;
VAL_ 1026 ICM_NM_LimpHome 0 "Not in limp home" 1 "Limp home" ;
VAL_ 1026 ICM_NM_SleepInd 0 "Bus needed" 1 "Bus not need, requesr sleep" ;
VAL_ 1026 ICM_NM_SleepAck 0 "Network still alive" 1 "Network sleep acknowledge" ;
VAL_ 1408 GPSTimeStatus 2 "GPS time unavailable use HU time" 1 "GPS time normal" 0 "GPS time invalid" ;
VAL_ 1408 TimeDisPlayFormat 0 "24-HR 24小时制" 1 "12-HR AM" 2 "12-HR PM" ;
VAL_ 1411 LightDelayOutSet 0 "0s" 1 "30s" 2 "60s" 3 "90s" 4 "120s" ;
VAL_ 1411 LightDelayInSet 0 "0s" 1 "15s" 2 "30s" 3 "45s" 4 "60s" ;
VAL_ 1411 HornAlertVolumeSet 0 "Normal" 1 "High" 2 "Low" 3 "OFF" ;
VAL_ 1411 SpeedLockValueSet 0 "40km/h Lock" 1 "15km/h Lock" 2 "OFF" ;
VAL_ 1411 WinDownByKeySet 0 "OFF" 1 "ON" ;
VAL_ 1411 AssistLightStateSet 0 "OFF" 1 "ON" ;
VAL_ 1411 WinCloseRainEnableSet 0 "OFF" 1 "ON" ;
VAL_ 1525 HU_TBOX_WiFi_Req 1 "Request" 0 "No request" ;
VAL_ 1525 HU_TBOX_SN_Req 1 "Request" 0 "No request" ;
VAL_ 1525 HU_TBOX_VIN_Req 1 "Request" 0 "No request" ;
VAL_ 1028 HU_NM_Alive 1 "Node alive" 0 "Node does not alive" ;
VAL_ 1028 HU_NM_Ring 1 "Ring  stable" 0 "Ring not stable" ;
VAL_ 1028 HU_NM_LimpHome 1 "limp home" 0 "Not in limp home" ;
VAL_ 1028 HU_NM_SleepInd 1 " Bus not need, requesr sleep" 0 "Bus needed" ;
VAL_ 1028 HU_NM_SleepAck 1 "Network sleep acknowledge" 0 "Network still alive" ;
VAL_ 865 PowerWindowPinchProtectionAlarm 0 "Default" 1 "Window Up Alarm" ;
VAL_ 865 RearWindowSuppressionStatus 0 "No Suppression（不抑制）" 1 "  Suppression（抑制）" ;
VAL_ 865 RemoteOpenWindow 0 "None Order" 1 "Executing" 2 "Implement" 3 "Implement fail" ;
VAL_ 865 RemoteCloseWindow 0 "None Order" 1 "Executing" 2 "Implement" 3 "Implement fail" ;
VAL_ 865 APMConditionNotCorrect 0 "None（default）" 1 "配置字无效" 2 "本地开关动作" 4 "钥匙遥控动作" 5 "电压低于9V后进入电源管理模式" 6 "触发防夹" ;
VAL_ 691 LDW_Warning 0 "No warning;" 1 "LD system is warning Left;" 2 "LD system is warning Right;" ;
VAL_ 691 FCW_Warning 0 "No warning;" 1 "Imminent Alert" 2 "Cautionary Alert" ;
VAL_ 691 camera_status 0 "normal" 1 " camera blocked摄像头遮挡" ;
VAL_ 691 LDW_Status 0 "LDW off系统关闭 " 1 "LDW standby系统开启 " 2 "LDW active系统激活 " 3 "LDW  failure系统故障" ;
VAL_ 691 FCW_Status 0 "FCW off系统关闭" 1 "FCW standby系统开启 " 2 "FCW active系统激活 " 3 "FCW  failure系统故障" ;
VAL_ 691 LDW_Button 0 "LDW disabledLDW系统开启" 1 "LDW enabled LDW系统开启" ;
VAL_ 691 FCW_Button 0 "FCW disabledFCW系统关闭" 1 "FCW enabledFCW系统开启" ;
VAL_ 691 LDWSResp 0 "LDWS  Disabled;" 1 "LDWS  Enabled;" ;
VAL_ 691 FCWResp 0 "FCW  Disabled;" 1 "FCW  Enabled;" ;
VAL_ 691 LDFC_NotWarning1 0 "Not YawRate" 1 " YawRate ≥14.5deg/s" ;
VAL_ 691 LDFC_NotWarning2 0 "Not steering wheel angle " 1 "Steering wheel angle" ;
VAL_ 691 LDFC_NotWarning3 0 "Brake padel position off" 1 "Brake padel position on制动踏板状态" ;
VAL_ 691 LDFC_NotWarning4 0 "Left Right  turn switch off" 1 "Left Right  turn switch on" ;
VAL_ 691 LDFC_NotWarning5 0 "Not GasPdlPsn" 1 " GasPdlPsn" ;
VAL_ 691 LDFC_NotWarning6 0 "Front wiper not  high" 1 " Front wiper high" ;
VAL_ 691 LeftLaneTrack 0 "Not tracking left side;" 1 "Tracking left side;" ;
VAL_ 691 RightLaneTrack 0 "Not tracking right side;" 1 "Tracking right side;" ;
VAL_ 691 RightLaneDistance 253 "Out of range/Unable to determine" 254 "Error" 255 "Init" ;
VAL_ 691 LeftLaneDistance 253 "Out of range/Unable to determine" 254 "Error" 255 "Init" ;
VAL_ 691 FrontObstacleDistance 253 "Out of range/Unable to determine" 254 "Error" 255 "Init" ;
VAL_ 1429 TimTyp_TCO 1 "Server time" 2 "GPS time" 3 "Estimate time" ;
VAL_ 1520 tbDoorCtrlReq 2 "Door Lock Request" 1 "Door Unlock Request" 0 "No Request" ;
VAL_ 1520 tbFindCarReq 1 "FindCar Request" 0 "No Request" ;
VAL_ 1520 tbWindowCtrlReq 2 "Window Close Request" 1 "Window Open Request" 0 "No Request" ;
VAL_ 1520 tbWinPosCtrlReqFL 0 "No Request" 1 "0% postion" 2 "10% postion" 3 "20% postion" 4 "30% postion" 5 "40% postion" 6 "50% postion" 7 "60% postion" 8 "70% postion" 9 "80% postion" 10 "90% postion" 11 "100% postion" 12 "上升一个档位" 13 "下降一个档位" ;
VAL_ 1520 tbWinPosCtrlReqFR 0 "No Request" 1 "0% postion" 2 "10% postion" 3 "20% postion" 4 "30% postion" 5 "40% postion" 6 "50% postion" 7 "60% postion" 8 "70% postion" 9 "80% postion" 10 "90% postion" 11 "100% postion" 12 "上升一个档位" 13 "下降一个档位" ;
VAL_ 1520 TelemaStatus 0 "idle" 1 "In Telematics Service" ;
VAL_ 1520 UpgradeSta 2 "Update succeed" 1 "Update failure" 0 "normal" ;
VAL_ 1521 OtaUpdateProgress 0 "0%" 1 "20%" 2 "40%" 3 "60%" 4 "80%" 5 "100%" ;
VAL_ 1521 OtaUpdateNotify 0 "有更新" 1 "无更新" ;
VAL_ 1521 OtaUpdateState 0 "满足" 1 "不满足" ;
VAL_ 1521 OtaUpdateResult 0 "成功" 1 "失败" ;
VAL_ 1037 TBOX_NM_Alive 1 "Node alive" 0 "Node does not alive" ;
VAL_ 1037 TBOX_NM_Ring 1 "Ring  stable" 0 "Ring not stable" ;
VAL_ 1037 TBOX_NM_LimpHome 1 "limp home" 0 "Not in limp home" ;
VAL_ 1037 TBOX_NM_SleepInd 1 " Bus not need, requesr sleep" 0 "Bus needed" ;
VAL_ 1037 TBOX_NM_SleepAck 1 "Network sleep acknowledge" 0 "Network still alive" ;
VAL_ 1413 OneHourWakeupflag 0 "Normal" 1 "1Hwakeup flag" ;
VAL_ 1413 TimTyp 1 "Server time" 2 "GPS time" 3 "Estimate time" ;
VAL_ 1672 LocationVd 0 "invalid" 1 "Valid" ;
VAL_ 1672 LatitudeDir 0 "North latitude" 1 "South latitude" ;
VAL_ 1672 LongitudeDir 0 "East longitude" 1 "West longitud" ;
VAL_ 1532 RmtACReq 0 "initial" 2 "RemoteAC Stop Request" 3 "RemoteAC Start Request" ;
VAL_ 1532 RmtChgReq 0 "initial" 2 "RemoteCharge Stop Request" 3 "RemoteCharge Start Request" ;
VAL_ 1532 LVBChgCmd 0 "No request" 1 "Request Charged Off" 2 "Request Charged On" ;
VAL_ 1532 MPPreHeatMode 0 "initial" 1 "High" 2 "Low" ;
VAL_ 279 CruSysSet 0 "inactive" 1 "active" ;
VAL_ 279 CruSysOn 0 "off" 1 "on" ;
VAL_ 279 BrkPdlPsnVd 0 "Not Valid" 1 "Valid" ;
VAL_ 279 BrkPdlPsnNC 0 "No apply" 1 "Applied" ;
VAL_ 279 BrkPdlPsnNO 0 "No apply" 1 "Applied" ;
VAL_ 279 GasPdlPsnVd 0 "not valid" 1 "valid" ;
VAL_ 600 Ready 0 "OFF" 1 "ON" ;
VAL_ 600 VCUKeySta 0 "KEY OFF" 1 "KEY ON" 2 "Ready" ;
VAL_ 600 GearPsn 0 "reserved" 1 "Position P" 2 "Position R" 3 "Position N" 4 "Position D" ;
VAL_ 600 IMMOFeedback 0 "IMMO check not OK" 1 "IMMO Check OK" ;
VAL_ 600 DriveModelFd 0 "nomal" 1 "ECO" 2 "Sport" ;
VAL_ 600 HCU_ShiftTipInfo 0 "No tip" 1 "Press the security button when shifting" 2 "Press the brake pedal when shifting" 3 "Stop the vehicle when shifting" 4 "Please release acceleration padel when shifting" 5 "Fault,can not in P please used EPB parking" 6 "Please shift the lever to right side" ;
VAL_ 600 VacuumPressureVd 0 "Invalid" 1 "Valid" ;
VAL_ 600 CruVehSpdVd 0 "Not Valid" 1 "Valid" ;
VAL_ 600 HVACHVforbidden 0 "NO forbidden" 1 "Forbidden" ;
VAL_ 600 BrkBkEgyFd 0 "Normal" 1 "OFF" 2 "Low" 3 "High" ;
VAL_ 600 VCUBrakelightReq 0 "NO request" 1 "Request" ;
VAL_ 600 CruVehSpd 0 "km/h (0x0 - 0x12C)" ;
VAL_ 825 EgyFlowSta 0 "Stoped" 1 "Drive" 2 "Recycling" ;
VAL_ 825 ReadyInd 0 "OFF" 1 "ON" ;
VAL_ 825 ChgLineInd 0 "OFF" 1 "ON" ;
VAL_ 825 TMFltInd 0 "OFF" 1 "ON" ;
VAL_ 825 LVBFltInd 0 "OFF" 1 "ON" ;
VAL_ 825 VCUFltInd 0 "OFF" 1 "ON" 2 "flashing" ;
VAL_ 825 SOCLowInd 0 "OFF" 1 "ON" ;
VAL_ 825 HVBFltInd 0 "OFF" 1 "ON" ;
VAL_ 825 lmtPowInd 0 "OFF" 1 "ON" ;
VAL_ 825 ChgStsInd 0 "OFF" 1 "ON" ;
VAL_ 825 HVBCutInd 0 "OFF" 1 "ON" ;
VAL_ 595 RemKm_Vd 0 "Invalid" 1 "Valid" ;
VAL_ 595 InsEgyConsptChangeFlg 0 "no change" 1 "Change" ;
VAL_ 595 AvgConsptModeFd 0 "initial" 1 "10 km" 2 "25 km" 2 "30 km" ;
VAL_ 1093 VCU_445Checksum 0 "Default" 1 "ChargeCondition notsatisfied" ;
VAL_ 1140 PlugSts 0 "Plug not insert" 1 "Plug insert and no charge" 2 "Plug insert and charging" ;
VAL_ 1140 ChgSta 0 "Initial value" 1 "Start charge；" 2 "Charge error" 3 "End of charge" ;
VAL_ 1140 TmgTimesetFlagFDMP5 0 "Initial value" 1 "Executing" 2 "Implement fail" ;
VAL_ 1140 TmgChgShowFB 0 "Initial value" 1 "start charge" 2 "stop charge" ;
VAL_ 1140 CAN_VCU_MP5_CHR_DISSATISFY 0 "Default" 1 "ChargeCondition notsatisfied" ;
VAL_ 1140 CAN_VCU_MP5_LTPROHB 0 "Default" 1 "ForbiddenLowTempCharge " 2 "AllowLowTempCharge" ;
VAL_ 1140 ChgStart 0 "No Charge" 1 "Start Charge" ;
VAL_ 1140 CAN_VCU_MP5_CHR_MODE 0 "Nocharge" 1 "NormalCharge" 2 "LonglifeCharge" 3 "LongMileageCharge" 4 "LowTempCharge" ;
VAL_ 1140 EgyFull 0 "No display" 1 "Display The battery is full" ;
VAL_ 430 ABSItvInProgress 0 "No Intervention" 1 "Intervention" ;
VAL_ 430 AYCItvInProgress 0 "No Intervention" 1 "Intervention" ;
VAL_ 430 TCSItvInProgress 0 "No Intervention" 1 "Intervention" ;
VAL_ 430 EBDitvinprogress 0 "No Intervention" 1 "Intervention" ;
VAL_ 430 VehSpdVd 0 "not valid" 1 "valid" ;
VAL_ 430 EngTqIncReqAct 0 "no engine torque increase request" 1 "engine torque increase request" ;
VAL_ 430 ABSWarningLamp 0 " No warning" 1 " Warning" ;
VAL_ 430 ESC_SYS_WarnLamp_EDR 0 " No warning" 1 " Warning" ;
VAL_ 430 EngTqDecReqAct 0 "no engine torque decrease request" 1 "engine torque decrease request" ;
VAL_ 430 EBDWarningLamp 0 " No warning" 1 " Warning" ;
VAL_ 517 LongAccVd 0 "Not valid" 1 "Valid" ;
VAL_ 517 HDCStatus 0 "off(HDC lamp off )" 1 "failure(HDC lamp on (Red))" 2 "on(HDC lamp on (Green) )" 3 "active(HDC lamp flash (Green))" ;
VAL_ 517 YawRateVd 0 "Not valid" 1 "Valid" ;
VAL_ 517 AYCFailure 0 "no failure" 1 "failure(ICM igniting ESC LAMP)" ;
VAL_ 517 EBDFailure 0 "no failure" 1 "failure(ICM igniting BRAKE LAMP)" ;
VAL_ 517 ABSFailure 0 "no failure" 1 "failure(ICM igniting ABS LAMP)" ;
VAL_ 517 TCSFailure 0 "no failure" 1 "failure((ICM igniting ESC LAMP)" ;
VAL_ 517 GearShiftForbidden 0 " No forbidden" 1 " Down shift forbidden" 2 " Up shift forbidden" 3 " Down & Up shift forbidden" ;
VAL_ 517 BrkPrsVd 0 "Not valid" 1 "valid" ;
VAL_ 533 ESCSw 0 "ESC switch on" 1 "ESC switch off" ;
VAL_ 533 ESCSwVd 0 "not valid" 1 "valid" ;
VAL_ 533 EPBRequest 0 "No request" 1 "Apply request" 2 "Release request" ;
VAL_ 533 AutoHoldActive 0 "Inactive" 1 "Active" ;
VAL_ 533 AutoHoldAvailable 1 "Available" 0 "Not available" ;
VAL_ 533 AutoholdFailure 0 "No failure" 1 "Failure" ;
VAL_ 533 HSAActive 0 " Not Active" 1 " Active" ;
VAL_ 533 HSAFailure 0 " no failure" 1 " failure" ;
VAL_ 533 AutoHazardBlinking 3 " Invalid signal" 2 " Reserved" 1 " AutoHazardBlinking ON" 0 " AutoHazardBlinking OFF" ;
VAL_ 533 GSensorCalibrationSt 0 "not in calibrating" 1 "in calibrating" 2 "calibration finished success" 3 "Calibration finished error" ;
VAL_ 533 AutoHoldSWStsVd 1 "Valid" 0 "Not valid" ;
VAL_ 533 AutoHoldSWSts 1 "on" 0 "off" ;
VAL_ 533 LatAccVd 0 "Not valid" 1 "Valid" ;
VAL_ 675 EPSFailure 1 "failed" 0 "Not failed" ;
VAL_ 675 EPS_StrModeFeedback 0 "Error" 1 "Normal" 2 "Comfort " 3 "Sport " ;
VAL_ 675 EPS_TorqSensorStatus 0 "not valid" 1 "valid" ;
VAL_ 675 EPS_CurrentConsumption 65535 "Invalid" ;
VAL_ 309 SAS_FailureSts 0 "No Failure " 1 "Failure " ;
VAL_ 309 SAS_CalibrationSts 0 "Sensor not calibrated" 1 "Sensor calibtrated" ;
VAL_ 309 SteeringWheelAngle 65535 "Sensor Error/ Sensor not calibrated" ;
VAL_ 309 SteeringWheelRotSpd 255 "Error " ;
VAL_ 309 SteeringWheelRotDir 1 "counterclockwise" 0 "clockwise or RotSpd  is 0" ;
VAL_ 125 AirbagFailSts 0 " Warning Lamp OFF" 1 " Warning Lamp ON " 3 " Error" ;
VAL_ 125 CrashInfo 0 "No crash" 1 "Crash occurred" ;
VAL_ 526 VehSpdVd 0 "not valid" 1 "valid" ;
VAL_ 526 EBS_FaultSts 0 "No Fault" 1 "Fault(Yellow Warning Lamp)  " 2 "Fault(Red Warning Lamp)" ;
VAL_ 526 EPBSts 0 "Unknown " 1 "ParkApplied " 2 "Released " 3 "CompletelyReleased(For mantenance)" 4 "Applying " 5 "Releasing " 6 "dynamicBraking" 7 "Reserved" ;
VAL_ 526 FailureLampSts 0 " Lamp Off" 1 " Lamp On" 2 " Lamp Flash" 3 " Reserved" ;
VAL_ 526 GearPsn_GW 0 "reserved" 1 "Position P" 2 "Position R" 3 "Position N" 4 "Position D" ;
VAL_ 945 ModeDisp 1 "Vent" 2 "VENT/FOOT" 3 "FOOT" 4 "DEF/FOOT" 5 "DEF" 8 "Auto" ;
VAL_ 945 RmtACReqFb 0 "None Order" 1 "Executing" 2 "Implement" 3 "Implement fail" ;
VAL_ 945 HVAC_State 0 "OFF" 1 "ON" ;
VAL_ 945 ExtTempVd 0 "not valid" 1 "valid" ;
VAL_ 945 HVAC_RearDefrost 0 "Not request" 1 "request" ;
VAL_ 945 BlowerLvl 0 "level 0" 1 "Level 1" 2 "Level 2" 3 "Level 3" 4 "Level 4" 5 "Level 5" 6 "Level 6" 7 "Level 7" 8 "Level 8" 9 "Level 9" ;
VAL_ 947 IndicatorAutoFront 0 "OFF;" 1 "ON;" ;
VAL_ 947 IndicatorDefrostFront 0 "OFF;" 1 "ON;" ;
VAL_ 947 IndicatorACFront 0 "OFF;" 1 "ON;" ;
VAL_ 947 IndicatorOFFFront 0 "OFF;" 1 "ON;" ;
VAL_ 947 IndicatorIntakeFront 0 "OFF;" 1 "ON;" ;
VAL_ 947 InternalRecycle 0 "OFF;" 1 "ON;" ;
VAL_ 947 HURequest 0 "No action;" 1 "Display HVAC information user interface page" ;
VAL_ 947 HUCancel 0 "No action;" 1 "Close (do not display)" ;
VAL_ 914 ECSta 0 "OFF" 3 "ON" ;
VAL_ 914 ECSts 0 "no warnning" 1 "Warnning" ;
VAL_ 914 ECost 0 "No limit" 1 "Limited" ;
VAL_ 1077 PTCRly1Ctl 0 "OFF" 3 "ON" ;
VAL_ 1077 PTCRly2Ctl 0 "OFF" 3 "ON" ;
VAL_ 1290 ParkWarnStatus_L 0 "No alarm" 1 "Standard alarm" 2 "Enhanced alarm" ;
VAL_ 1290 LCMAStatus_L 0 "No alarm" 1 "Standard alarm" 2 "Enhanced alarm" ;
VAL_ 1290 CrossTrafficAlertSt_L 0 "No alarm" 1 "Standard alarm" 2 "Enhanced alarm" ;
VAL_ 1290 BlindSpotDetectionStayus_L 0 "No alarm" 1 "Standard alarm" 2 "Enhanced alarm" ;
VAL_ 1290 BSDSysStatus 0 " SENSOR_OFF" 1 " SENSOR_NORMAL_WORK" 2 " SENSOR_ERROR" 3 " sensor_blindness" ;
VAL_ 1290 DOW_Status 0 " OFF" 1 " Passive" 2 " Active" 3 " Reserved" ;
VAL_ 1290 BSD_Status 0 " OFF" 1 " Passive" 2 " Active" 3 " Reserved" ;
VAL_ 1290 LCA_Status 0 " OFF" 1 " Passive" 2 " Active" 3 " Reserved" ;
VAL_ 1290 RCTA_Status 0 " OFF" 1 " Passive" 2 " Active" 3 " Reserved" ;
VAL_ 704 ParkWarnStatus_R 0 "No alarm" 1 "Standard alarm" 2 "Enhanced alarm" ;
VAL_ 704 LCMAStatus_R 0 "No alarm" 1 "Standard alarm" 2 "Enhanced alarm" ;
VAL_ 704 CrossTrafficAlertSt_R 0 "No alarm" 1 "Standard alarm" 2 "Enhanced alarm" ;
VAL_ 704 BlindSpotDetectionStayus_R 0 "No alarm" 1 "Standard alarm" 2 "Enhanced alarm" ;
VAL_ 704 BSDSysStatus 0 " SENSOR_OFF" 1 " SENSOR_NORMAL_WORK" 2 " SENSOR_ERROR" 3 " sensor_blindness" ;
VAL_ 704 DOW_Status 0 " OFF" 1 " Passive" 2 " Active" 3 " Reserved" ;
VAL_ 704 BSD_Status 0 " OFF" 1 " Passive" 2 " Active" 3 " Reserved" ;
VAL_ 704 LCA_Status 0 " OFF" 1 " Passive" 2 " Active" 3 " Reserved" ;
VAL_ 704 RCTA_Status 0 " OFF" 1 " Passive" 2 " Active" 3 " Reserved" ;
VAL_ 915 AEBS_Status_WS 0 "not ready（上电后1.5s初始化" 1 "temporarily not available（系统有故障）" 2 "system is deactived bu driver（被驾驶员关闭）" 3 "system is ready" 4 "driver overrides system（抑制条件包括猛打方向盘、猛踩油门）" 5 "collision warning active（一级报警）" 6 "clooision warning with braking（二级报警+点刹AWB）" 7 "emergency braking active（AEB触发）" ;
VAL_ 915 AEBS_ActiveState_WS 0 "No_Action(没触发）" 1 "Normal" 2 "Abnormal（车辆没响应）" 3 "No_Respond" ;
VAL_ 915 BrakePedalSwitchStatus_WS 0 " No apply" 1 " Applied" ;
VAL_ 916 AEBS_Status_WD 0 "not ready（上电后1.5s初始化" 1 "temporarily not available（系统有故障）" 2 "system is deactived bu driver（被驾驶员关闭）" 3 "system is ready" 4 "driver overrides system（抑制条件包括猛打方向盘、猛踩油门）" 5 "collision warning active（一级报警）" 6 "clooision warning with braking（二级报警+点刹AWB）" 7 "emergency braking active（AEB触发）" ;
VAL_ 916 AEBS_ActiveState_WD 0 "No_Action" 1 "Normal" 2 "Abnormal" 3 "No_Respond" ;
VAL_ 916 BrakePedalSwitchStatus_WD 0 " No apply" 1 " Applied" ;
VAL_ 917 AEBS_Status_BS 0 "not ready（上电后1.5s初始化" 1 "temporarily not available（系统有故障）" 2 "system is deactived bu driver（被驾驶员关闭）" 3 "system is ready" 4 "driver overrides system（抑制条件包括猛打方向盘、猛踩油门）" 5 "collision warning active（一级报警）" 6 "clooision warning with braking（二级报警+点刹AWB）" 7 "emergency braking active（AEB触发）" ;
VAL_ 917 AEBS_ActiveState_BS 0 "No_Action" 1 "Normal" 2 "Abnormal" 3 "No_Respond" ;
VAL_ 917 BrakePedalSwitchStatus_BS 0 " No apply" 1 " Applied" ;
VAL_ 918 AEBS_Status_BD 0 "not ready（上电后1.5s初始化" 1 "temporarily not available（系统有故障）" 2 "system is deactived bu driver（被驾驶员关闭）" 3 "system is ready" 4 "driver overrides system（抑制条件包括猛打方向盘、猛踩油门）" 5 "collision warning active（一级报警）" 6 "clooision warning with braking（二级报警+点刹AWB）" 7 "emergency braking active（AEB触发）" ;
VAL_ 918 AEBS_ActiveState_BD 0 "No_Action" 1 "Normal" 2 "Abnormal" 3 "No_Respond" ;
VAL_ 918 BrakePedalSwitchStatus_BD 0 " No apply" 1 " Applied" ;
VAL_ 919 AEBStatus 0 " OFF mode（软开关没开）" 1 "  ON" 2 "Temporary Failure（当前上电周期可恢复，一般是短时通讯故障）" 3 " Permanent Failure" ;
VAL_ 919 LineRightWarning 0 " No Warning" 1 " Warning" ;
VAL_ 919 LineLeftWarning 0 " No Warning" 1 " Warning" ;
VAL_ 919 FCWWarning 0 " No warning" 1 " Lvl1WarningForVeh " 2 "Lvl1WarningForPed" 3 " Lvl2WarningForVeh " 4 "Lvl2WarningForPed" 7 "Invalid" ;
VAL_ 919 SensorStatus 0 "normal" 1 "radar missalign" 2 "radar blindness" 3 "camera missalign" 4 "camera blindness" ;
VAL_ 919 LDWStatus 0 " OFF mode" 1 "  ON" 2 "Temporary Failure" 3 " Permanent Failure" ;
VAL_ 919 LineLeft_Type 0 " No display" 1 " Solid lane" 2 " dash lane" 3 " Reserved" ;
VAL_ 919 LineRight_Type 0 " No display" 1 " Solid lane" 2 " dash lane" 3 " Reserved" ;
VAL_ 500 BSD_FUNCTION_SW 0 "Off" 1 "On" ;
VAL_ 500 Poslamp 0 "OFF" 1 "ON" ;
VAL_ 500 Trunk_BackDoor_Sts 0 "close" 1 "open" ;
VAL_ 500 PsgDoorStatus 0 "close" 1 "open" ;
VAL_ 500 RRDoorStatus 0 "close" 1 "open" ;
VAL_ 500 RLDoorStatus 0 "close" 1 "open" ;
VAL_ 500 DRVUnlockState 0 "lock" 1 "unlock" ;
VAL_ 500 DefrostCtrl 0 "off" 1 "on" ;
VAL_ 500 DrvDoorStatus 0 "Door is close." 1 "Door is open" ;
VAL_ 500 OccupantDetDRVSideVd 0 " not valid" 1 " valid" ;
VAL_ 500 HeadLampLowBeamCtrl 0 "Off" 1 "On" ;
VAL_ 500 HeadLampHighBeamCtrl 0 "Off" 1 "On" ;
VAL_ 500 LDW_SWSet 0 "LDWS  Disabled;" 1 "LDWS  Enabled;" ;
VAL_ 500 KeyState_GW 0 "OFF" 1 "ACC" 2 "IGN" 3 "CRANK+IG" 7 "Error" ;
VAL_ 500 HoodStatus 0 "Door is close." 1 "Door is open" ;
VAL_ 500 OccupantDetDRVSide 0 "unbelted" 1 "belted" ;
VAL_ 500 AEBSet 0 "AEB  Disabled;" 1 "AEB  Enabled;" ;
VAL_ 500 TurnSwitch_GW 0 " OFF" 1 " Left" 2 " Right" 3 " Error" ;
VAL_ 500 FrontWiperStatus_GW 2 "Wiper high " 1 "Wiper low " 0 "wiper off" ;
VAL_ 500 DirIndicationLeft_GW 1 "ON" 0 "OFF" ;
VAL_ 500 DirIndicationRight_GW 1 "ON" 0 "OFF" ;
VAL_ 500 HazardWarningLightStatus 0 "OFF" 1 "ON" ;
VAL_ 500 BCM_KeyState_VD 0 "Inalid" 3 "Valid" ;
VAL_ 500 Checksumof1F4 0 " 0-255" ;
VAL_ 500 TurnSwitchVd 0 " not valid" 1 " valid" ;
VAL_ 500 Counterof1F4 0 " 0-15" ;
VAL_ 500 StrModeSelect 0 "No request" 1 "Normal" 2 "Comfort" 3 "Sport" ;
VAL_ 572 WhlSpdFRVd 3 "valid" 0 "not valid" ;
VAL_ 572 WhlSpdFLVd 3 "valid" 0 "not valid" ;
VAL_ 573 WhlSpdRRVd 3 "valid" 0 "not valid" ;
VAL_ 573 WhlSpdRLVd 3 "valid" 0 "not valid" ;
VAL_ 810 FLWheelDir 0 "Forward" 1 "Backward" 2 "Unknow" ;
VAL_ 810 FRWheelDir 0 "Forward" 1 "Backward" 2 "Unknow" ;
VAL_ 810 RLWheelDir 0 "Forward" 1 "Backward" 2 "Unknow" ;
VAL_ 810 RRWheelDir 0 "Forward" 1 "Backward" 2 "Unknow" ;
